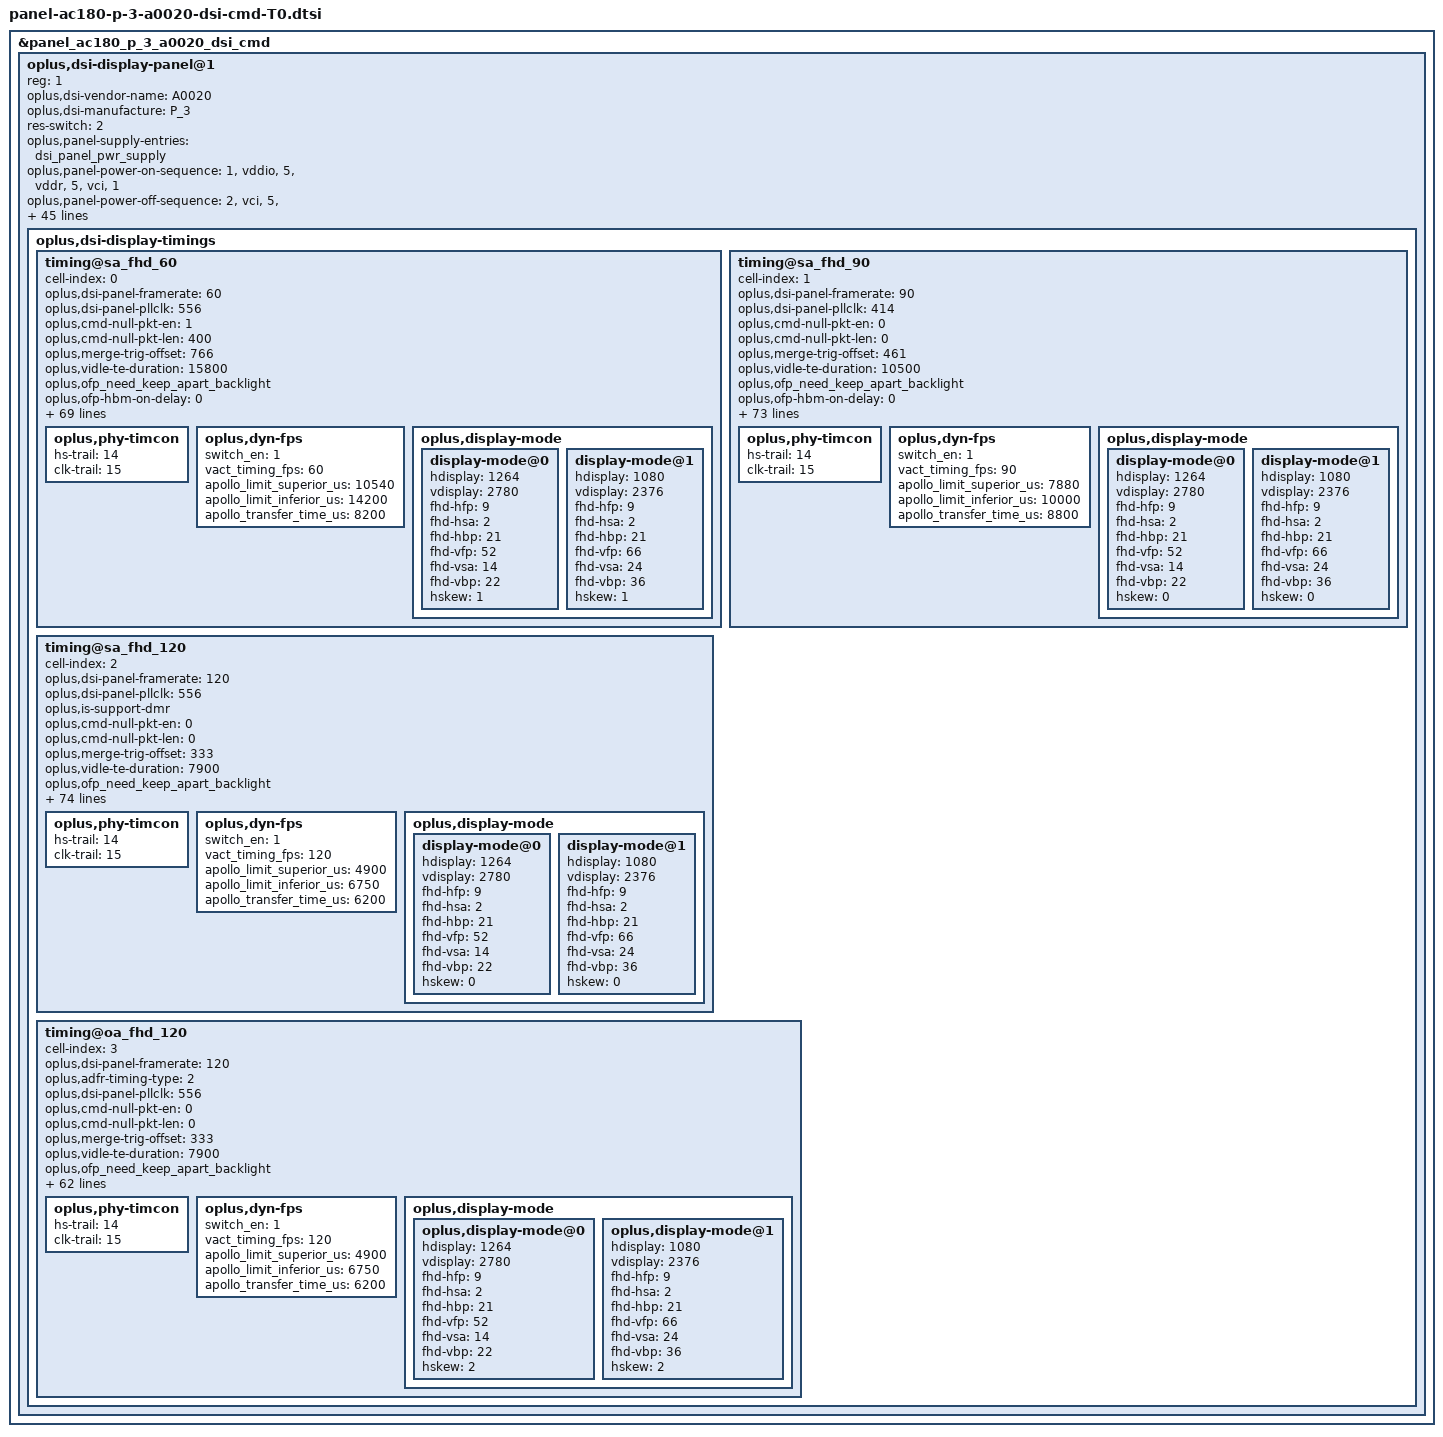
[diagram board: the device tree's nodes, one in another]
&panel_ac180_p_3_a0020_dsi_cmd {
	oplus,dsi-display-panel@1 {
		reg = <1>;
		oplus,dsi-vendor-name = "A0020";
		oplus,dsi-manufacture = "P_3";
		/* round corner */
		#include "panel-ac180-p-3-a0020-dsi-cmd-round-corner.dtsi"
		oplus,dsi-display-timings {
			timing@sa_fhd_60 {
				cell-index = <0>;
				oplus,dsi-panel-framerate = <60>;
				oplus,dsi-panel-pllclk = <556>;
				oplus,cmd-null-pkt-en = <1>;
				oplus,cmd-null-pkt-len = <400>;
				oplus,merge-trig-offset = <766>;
				oplus,vidle-te-duration = <15800>;
				/* OPLUS_FEATURE_DISPLAY_ONSCREENFINGERPRINT */
				oplus,ofp_need_keep_apart_backlight;
				oplus,ofp-hbm-on-delay = <0>;
				oplus,ofp-pre-hbm-off-delay = <12>;
				oplus,ofp-hbm-off-delay = <0>;
				oplus,ofp-need-to-sync-data-in-aod-unlocking;
				oplus,ofp-aod-off-insert-black = <2>;
				oplus,ofp-aod-off-black-frame-total-time = <59>;
				#include "panel-ac180-p-3-a0020-dsi-cmd-common-T0.dtsi"
				oplus,dsi-timing-switch-command = [
					39 00 00 40 00 00 04 FF 5A A5 00
					39 00 00 40 00 00 02 60 00 // 0x00: 120Hz 02: 90Hz
					39 00 00 40 00 00 04 FF 5A A5 53
					39 00 00 40 00 00 03 85 CC E1 // Normal Demura
					39 00 00 40 00 00 04 FF 5A A5 2D
					39 00 00 40 00 00 03 83 01 00
					39 00 00 40 00 00 02 F2 01
					39 00 00 00 00 00 04 FF 5A A5 00
				];
				oplus,dsi-timing-switch-1pulse-command = [
					39 00 00 40 00 00 04 FF 5A A5 00
					39 00 00 40 00 00 02 60 01 // 0x01: 120Hz 03: 90Hz
					39 00 00 40 00 00 04 FF 5A A5 53
					39 00 00 40 00 00 03 85 CC E3 // DC Demura
					39 00 00 40 00 00 04 FF 5A A5 2D
					39 00 00 40 00 00 03 84 01 00
					39 00 00 40 00 00 02 F2 01
					39 00 00 00 00 00 04 FF 5A A5 00
				];
				oplus,dsi-on-command = [
					39 00 00 00 00 00 04 FF 5A A5 08
					39 00 00 00 00 00 02 C8 62 // Sleep out don't reload
					39 00 00 00 00 00 04 FF 5A A5 10 //lhbm mode control begin
					39 00 00 00 00 00 27 8F C8 7C 00 42 00 80 10 00 5A 00 59 58 00 40 1F 00 0D 08 00 05 03 00 02 00 00 00 00 00 00 00 00 00 00 00 00 00 00 00
					39 00 00 00 00 00 04 FF 5A A5 24
					39 00 00 00 00 00 09 A5 0F FF 0F FE 0D BB 0B 1A
					39 00 00 00 00 00 09 A6 07 52 04 8B 04 8A 04 76
					39 00 00 00 00 00 09 A7 03 E6 02 CB 01 E1 01 7D
					39 00 00 00 00 00 09 A8 01 19 00 B5 00 01 00 00
					39 00 00 00 00 00 09 A9 00 00 00 00 00 00 00 00
					39 00 00 00 00 00 09 AA 00 00 00 00 00 00 00 00
					39 00 00 00 00 00 03 AB 00 00
					39 00 00 00 00 00 04 FF 5A A5 29
					39 00 00 00 00 00 09 93 0F FF 0F FE 0D BB 0B 1A
					39 00 00 00 00 00 09 94 07 52 04 8B 04 8A 04 76
					39 00 00 00 00 00 09 95 03 E6 02 CB 01 E1 01 7D
					39 00 00 00 00 00 09 96 01 19 00 B5 00 01 00 00
					39 00 00 00 00 00 09 97 00 00 00 00 00 00 00 00
					39 00 00 00 00 00 09 98 00 00 00 00 00 00 00 00
					39 00 00 00 00 00 09 99 00 00 00 00 00 00 00 00
					39 00 00 00 00 00 05 9A 00 00 00 00
					39 00 00 00 00 00 04 FF 5A A5 00
					39 00 00 00 00 00 02 4F 31
					39 00 00 00 00 00 04 FF 5A A5 1E
					39 00 00 00 00 00 02 80 89
					39 00 00 00 00 00 02 85 10
					39 00 00 00 00 00 02 9A 3F
					39 00 00 00 00 00 02 9B 01
					39 00 00 00 00 00 18 94 00 00 23 00 68 CF 12 58 03 23 D0 BF 46 D0 03 78 58 CF AC 68 23 0E 00
					39 00 00 00 00 00 19 95 00 00 12 00 46 9C 11 14 AE 23 6A 48 45 48 6A 68 AE 14 9B 9C 46 DF 12 00
					39 00 00 00 00 00 0D 96 FD F3 E6 CD B3 9A 80 66 4D 33 1A 00
					39 00 00 00 00 00 13 97 00 29 CC 13 98 30 46 C8 60 79 F8 90 BC 28 C0 EF 58 F0
					39 00 00 00 00 00 04 FF 5A A5 1F
					39 00 00 00 00 00 02 C0 08
					39 00 00 00 00 00 04 FF 5A A5 00
					39 00 00 00 00 00 02 6E 00
					39 00 00 00 00 00 04 FF 5A A5 1E
					39 00 00 00 00 00 02 C0 10
					39 00 00 00 00 00 04 C1 70 9C C1
					39 00 00 00 00 00 09 C2 FF FF FF 61 36 63 46 00
					39 00 00 00 00 00 27 C5 44 00 00 44 00 00 44 00 00 33 FE F7 32 72 77 11 A7 6C 11 3B 08 00 C1 00 00 00 00 00 00 00 00 00 00 00 00 00 00 00
					39 00 00 00 00 00 09 C6 44 00 00 21 00 00 00 80
					39 00 00 00 00 00 27 C7 44 00 00 33 8B 17 21 19 58 11 55 50 10 22 D8 00 99 59 00 00 00 00 00 00 00 00 00 00 00 00 00 00 00 00 00 00 00 00
					39 00 00 00 00 00 09 C8 44 00 00 32 00 00 01 00
					39 00 00 00 00 00 02 C9 30
					39 00 00 00 00 00 04 FF 5A A5 1F
					39 00 00 00 00 00 02 C0 08
					39 00 00 00 00 00 1F C2 FF FF FF AB EA FF FF FF FC FC FF FC FC FC FF FF FF FF FF FF FF FF FF FF FF FF FF FF FF FF
					39 00 00 00 00 00 04 FF 5A A5 24
					39 00 00 00 00 00 02 80 04
					39 00 00 00 00 00 02 81 8B
					39 00 00 00 00 00 02 82 0F
					39 00 00 00 00 00 02 83 FE
					39 00 00 00 00 00 02 84 00
					39 00 00 00 00 00 04 FF 5A A5 00
					39 00 00 00 00 00 02 95 FF
					39 00 00 00 00 00 02 96 09
					39 00 00 00 00 00 02 97 D9
					39 00 00 00 00 00 02 98 02
					39 00 00 00 00 00 02 99 78 //lhbm mode control end
					39 00 00 00 00 00 04 FF 5A A5 07
					39 00 00 00 00 00 02 8A 01 // PPS Enable
					39 00 00 00 00 00 03 8B 11 E0 // PPS Table
					39 00 00 00 00 00 64 80 00 00 00 00 00 12 00 00 A0 21 00 0A DC 04 F0 00 0A 02 78 02 78 01 55 01 D0 00 0A 00 89 00 35 00 0C 0A AB 31 07 08 00 0C 10 07 10 20 00 06 0F 0F 33 0E 1C 2A 38 46 54 62 69 70 77 79 7B 7D 7E 00 82 11 40 19 C0 22 3E 32 7C 3A BA 3A F8 3B 38 3B 38 3B 76 4B 76 4B 74 4B 74 5B B4 73 F4 01 00 00 00 00 00
					39 00 00 00 00 00 64 81 00 00 00 00 00 12 00 00 AB 30 80 0A DC 04 F0 00 14 02 78 02 78 02 00 02 57 00 20 01 F8 00 08 00 0D 05 7A 04 4F 18 00 10 E0 07 10 20 00 06 0F 0F 33 0E 1C 2A 38 46 54 62 69 70 77 79 7B 7D 7E 02 02 22 00 2A 40 2A BE 3A FC 3A FA 3A F8 3B 38 3B 78 3B B6 4B B6 4B F4 4B F4 6C 34 84 74 00 00 00 00 00 00
					39 00 00 00 00 00 02 91 00
					39 00 00 00 00 00 04 FF 5A A5 07
					39 00 00 00 00 00 03 8B 11 A0
					39 00 00 00 00 00 04 FF 5A A5 14
					39 00 00 00 00 00 02 82 01 // SPR IN AP ON
					39 00 00 00 00 00 04 FF 5A A5 21
					39 00 00 00 00 00 02 A4 18 // Flash reload enable
					39 00 00 00 00 00 04 FF 5A A5 13
					39 00 00 00 00 00 03 FB 18 27 // Hole related
					39 00 00 00 00 00 04 FF 5A A5 2D
					39 00 00 00 00 00 02 F2 01 // 0x00:120Hz 01:60Hz
					39 00 00 00 00 00 03 83 01 00 // 60Hz skip frame
					39 00 00 00 00 00 03 84 00 00 // 120Hz skip frame (1pulse)
					39 00 00 00 00 00 03 85 00 00 // 90Hz skip frame
					39 00 00 00 00 00 03 86 00 00 // 90Hz skip frame (1pulse)
					39 00 00 00 00 00 04 FF 5A A5 00
					39 00 00 00 00 00 02 5A 01 // ADFR
					39 00 00 00 00 00 02 5B 80 // ADFR
					39 00 00 00 00 00 04 FF 5A A5 02
					39 00 00 00 00 00 02 C0 03
					39 00 00 00 00 00 04 FF 5A A5 2D
					39 00 00 00 00 00 04 EC 01 AF 00
					39 00 00 00 00 00 03 93 A0 00
					39 00 00 00 00 00 03 94 C4 00
					39 00 00 00 00 00 03 95 00 00
					39 00 00 00 00 00 03 96 00 00
					39 00 00 00 00 00 03 ED D5 00
					39 00 00 00 00 00 04 EE 00 00 00
					/* decreasing step */
					39 00 00 00 00 00 02 97 03
					39 00 00 00 00 00 02 B1 03
					39 00 00 00 00 00 03 98 03 00
					39 00 00 00 00 00 03 99 05 00
					39 00 00 00 00 00 03 9A 0B 00
					39 00 00 00 00 00 03 9B 17 00
					39 00 00 00 00 00 03 A0 00 00
					39 00 00 00 00 00 03 A1 01 02
					39 00 00 00 00 00 02 B2 02
					39 00 00 00 00 00 02 B3 04
					39 00 00 00 00 00 02 B4 08
					39 00 00 00 00 00 02 B5 11
					39 00 00 00 00 00 03 BA 00 00
					39 00 00 00 00 00 03 BB 01 02
					39 00 00 00 00 00 04 FF 5A A5 02
					39 00 00 00 00 00 09 B0 00 80 00 10 00 00 00 00
					39 00 00 00 00 00 03 AB AF 82 // TE Left Shift 2ms
					39 00 00 00 00 00 04 FF 5A A5 31
					39 00 00 00 00 00 02 A0 A1 // CTB ON
					39 00 00 00 00 00 04 FF 5A A5 49
					39 00 00 00 00 00 02 E0 01 // ODC ON
					39 00 00 00 00 00 04 FF 5A A5 53
					39 00 00 00 00 00 03 80 0F 40 // Demura ON
					39 00 00 00 00 00 03 85 CC E1 // Loading demura data
					39 00 00 00 00 00 04 FF 5A A5 17
					39 00 00 00 00 00 02 A0 00 // RCN OFF
					/* AVEE PUMP 4H */
					39 00 00 00 00 00 04 FF 5A A5 02
					39 00 00 00 00 00 0A E5 09 0B 0B 0D 55 0D 32 32 32
					39 00 00 00 00 00 03 E7 33 25
					39 00 00 00 00 00 03 E8 33 25
					39 00 00 00 00 00 03 E9 33 25
					39 00 00 00 00 00 03 EA 33 25
					39 00 00 00 00 00 04 FF 5A A5 12
					39 00 00 00 00 00 02 81 33 // SRC keep vsp 2 frame
					39 00 00 00 00 00 04 FF 5A A5 00
					39 00 00 00 00 00 02 5E 01 // Skip frame Enable
					39 00 00 00 00 00 02 60 00 // Normal mode: 60Hz (6pulse)
					39 00 00 00 00 00 02 61 07 // AOD in mode
					39 00 00 00 00 00 02 35 00 // TE On
					39 00 00 00 00 00 02 53 20 // BC On Dimming OFF

					/* 3D LUT register */
					/* 3D LUT switch */
					39 00 00 40 00 00 04 FF 5A A5 00
					15 00 00 40 00 00 02 4D 00
					/* Gray binding points and DBV */
					39 00 00 40 00 00 04 FF 5A A5 4F
					15 00 00 40 00 00 02 91 00
					15 00 00 40 00 00 02 92 00
					15 00 00 40 00 00 02 93 08
					15 00 00 40 00 00 02 94 00
					15 00 00 40 00 00 02 95 10
					15 00 00 40 00 00 02 96 00
					15 00 00 40 00 00 02 97 20
					15 00 00 40 00 00 02 98 00
					15 00 00 40 00 00 02 99 20
					15 00 00 40 00 00 02 9A 00
					15 00 00 40 00 00 02 A0 00
					15 00 00 40 00 00 02 A1 01
					15 00 00 40 00 00 02 A2 0A
					15 00 00 40 00 00 02 A3 81
					15 00 00 40 00 00 02 A4 0F
					15 00 00 40 00 00 02 A5 FF
					/* Matrix_off && LUT3D_off && Gray2bypass */
					15 00 00 40 00 00 02 AC 0C
					/* Gamma && Degamma */
					39 00 00 40 00 00 04 FF 5A A5 13
					15 00 00 40 00 00 02 CA 70
					/* 125 point mapping value for DBV1 */
					39 00 00 40 00 00 04 FF 5A A5 70
					39 00 00 40 00 00 07 80 00 00 00 00 00 00
					39 00 00 40 00 00 07 81 00 00 00 00 09 99
					39 00 00 40 00 00 07 82 00 00 00 00 13 33
					39 00 00 40 00 00 07 83 00 00 00 00 20 04
					39 00 00 40 00 00 07 84 00 00 00 00 3F BC
					39 00 00 40 00 00 07 85 00 00 08 04 00 00
					39 00 00 40 00 00 07 86 00 00 08 04 08 04
					39 00 00 40 00 00 07 87 00 00 08 04 10 04
					39 00 00 40 00 00 07 88 00 00 08 04 20 04
					39 00 00 40 00 00 07 89 00 00 08 04 3F BC
					39 00 00 40 00 00 07 8A 00 00 10 04 00 00
					39 00 00 40 00 00 07 8B 00 00 10 04 08 04
					39 00 00 40 00 00 07 8C 00 00 10 04 10 04
					39 00 00 40 00 00 07 8D 00 00 10 04 20 04
					39 00 00 40 00 00 07 8E 00 00 10 04 3F BC
					39 00 00 40 00 00 07 8F 00 00 20 04 00 00
					39 00 00 40 00 00 07 90 00 00 20 04 08 04
					39 00 00 40 00 00 07 91 00 00 20 04 10 04
					39 00 00 40 00 00 07 92 00 00 20 04 20 04
					39 00 00 40 00 00 07 93 00 00 20 04 3F BC
					39 00 00 40 00 00 07 94 00 00 3F BC 00 00
					39 00 00 40 00 00 07 95 00 00 3F BC 08 04
					39 00 00 40 00 00 07 96 00 00 3F BC 10 04
					39 00 00 40 00 00 07 97 00 00 3F BC 20 04
					39 00 00 40 00 00 07 98 00 00 3F BC 3F BC
					39 00 00 40 00 00 07 99 04 CC 00 00 00 00
					39 00 00 40 00 00 07 9A 08 04 00 00 08 04
					39 00 00 40 00 00 07 9B 08 04 00 00 10 04
					39 00 00 40 00 00 07 9C 08 04 00 00 20 04
					39 00 00 40 00 00 07 9D 08 04 00 00 3F BC
					39 00 00 40 00 00 07 9E 08 04 08 04 00 00
					39 00 00 40 00 00 07 9F 04 CC 08 00 09 99
					39 00 00 40 00 00 07 A0 08 04 08 04 10 04
					39 00 00 40 00 00 07 A1 08 04 08 04 20 04
					39 00 00 40 00 00 07 A2 08 04 08 04 3F BC
					39 00 00 40 00 00 07 A3 08 04 10 04 00 00
					39 00 00 40 00 00 07 A4 08 04 10 04 08 04
					39 00 00 40 00 00 07 A5 08 04 10 04 10 04
					39 00 00 40 00 00 07 A6 08 04 10 04 20 04
					39 00 00 40 00 00 07 A7 08 04 10 04 3F BC
					39 00 00 40 00 00 07 A8 08 04 20 04 00 00
					39 00 00 40 00 00 07 A9 08 04 20 04 08 04
					39 00 00 40 00 00 07 AA 08 04 20 04 10 04
					39 00 00 40 00 00 07 AB 08 04 20 04 20 04
					39 00 00 40 00 00 07 AC 08 04 20 04 3F BC
					39 00 00 40 00 00 07 AD 08 04 3F BC 00 00
					39 00 00 40 00 00 07 AE 08 04 3F BC 08 04
					39 00 00 40 00 00 07 AF 08 04 3F BC 10 04
					39 00 00 40 00 00 07 B0 08 04 3F BC 20 04
					39 00 00 40 00 00 07 B1 08 04 3F BC 3F BC
					39 00 00 40 00 00 07 B2 09 99 00 00 00 00
					39 00 00 40 00 00 07 B3 10 04 00 00 08 04
					39 00 00 40 00 00 07 B4 10 04 00 00 10 04
					39 00 00 40 00 00 07 B5 10 04 00 00 20 04
					39 00 00 40 00 00 07 B6 10 04 00 00 3F BC
					39 00 00 40 00 00 07 B7 10 04 08 04 00 00
					39 00 00 40 00 00 07 B8 10 04 08 04 08 04
					39 00 00 40 00 00 07 B9 10 04 08 04 10 04
					39 00 00 40 00 00 07 BA 10 04 08 04 20 04
					39 00 00 40 00 00 07 BB 10 04 08 04 3F BC
					39 00 00 40 00 00 07 BC 10 04 10 04 00 00
					39 00 00 40 00 00 07 BD 10 04 10 04 08 04
					39 00 00 40 00 00 07 BE 09 99 10 04 13 33
					39 00 00 40 00 00 07 BF 10 04 10 04 20 04
					39 00 00 40 00 00 07 C0 10 04 10 04 3F BC
					39 00 00 40 00 00 07 C1 10 04 20 04 00 00
					39 00 00 40 00 00 07 C2 10 04 20 04 08 04
					39 00 00 40 00 00 07 C3 10 04 20 04 10 04
					39 00 00 40 00 00 07 C4 10 04 20 04 20 04
					39 00 00 40 00 00 07 C5 10 04 20 04 3F BC
					39 00 00 40 00 00 07 C6 10 04 3F BC 00 00
					39 00 00 40 00 00 07 C7 10 04 3F BC 08 04
					39 00 00 40 00 00 07 C8 10 04 3F BC 10 04
					39 00 00 40 00 00 07 C9 10 04 3F BC 20 04
					39 00 00 40 00 00 07 CA 10 04 3F BC 3F BC
					39 00 00 40 00 00 07 CB 20 04 00 00 00 00
					39 00 00 40 00 00 07 CC 20 04 00 00 08 04
					39 00 00 40 00 00 07 CD 20 04 00 00 10 04
					39 00 00 40 00 00 07 CE 20 04 00 00 20 04
					39 00 00 40 00 00 07 CF 20 04 00 00 3F BC
					39 00 00 40 00 00 07 D0 20 04 08 04 00 00
					39 00 00 40 00 00 07 D1 20 04 08 04 08 04
					39 00 00 40 00 00 07 D2 20 04 08 04 10 04
					39 00 00 40 00 00 07 D3 20 04 08 04 20 04
					39 00 00 40 00 00 07 D4 20 04 08 04 3F BC
					39 00 00 40 00 00 07 D5 20 04 10 04 00 00
					39 00 00 40 00 00 07 D6 20 04 10 04 08 04
					39 00 00 40 00 00 07 D7 20 04 10 04 10 04
					39 00 00 40 00 00 07 D8 20 04 10 04 20 04
					39 00 00 40 00 00 07 D9 20 04 10 04 3F BC
					39 00 00 40 00 00 07 DA 20 04 20 04 00 00
					39 00 00 40 00 00 07 DB 20 04 20 04 08 04
					39 00 00 40 00 00 07 DC 20 04 20 04 10 04
					39 00 00 40 00 00 07 DD 20 00 20 00 20 00
					39 00 00 40 00 00 07 DE 20 04 20 04 3F BC
					39 00 00 40 00 00 07 DF 20 04 3F BC 00 00
					39 00 00 40 00 00 07 E0 20 04 3F BC 08 04
					39 00 00 40 00 00 07 E1 20 04 3F BC 10 04
					39 00 00 40 00 00 07 E2 20 04 3F BC 20 04
					39 00 00 40 00 00 07 E3 20 04 3F BC 3F BC
					39 00 00 40 00 00 07 E4 3F BC 00 00 00 00
					39 00 00 40 00 00 07 E5 3F BC 00 00 08 04
					39 00 00 40 00 00 07 E6 3F BC 00 00 10 04
					39 00 00 40 00 00 07 E7 3F BC 00 00 20 04
					39 00 00 40 00 00 07 E8 3F BC 00 00 3F BC
					39 00 00 40 00 00 07 E9 3F BC 08 04 00 00
					39 00 00 40 00 00 07 EA 3F BC 08 04 08 04
					39 00 00 40 00 00 07 EB 3F BC 08 04 10 04
					39 00 00 40 00 00 07 EC 3F BC 08 04 20 04
					39 00 00 40 00 00 07 ED 3F BC 08 04 3F BC
					39 00 00 40 00 00 07 EE 3F BC 10 04 00 00
					39 00 00 40 00 00 07 EF 3F BC 10 04 08 04
					39 00 00 40 00 00 07 F0 3F BC 10 04 10 04
					39 00 00 40 00 00 07 F1 3F BC 10 04 20 04
					39 00 00 40 00 00 07 F2 3F BC 10 04 3F BC
					39 00 00 40 00 00 07 F3 3F BC 20 04 00 00
					39 00 00 40 00 00 07 F4 3F BC 20 04 08 04
					39 00 00 40 00 00 07 F5 3F BC 20 04 10 04
					39 00 00 40 00 00 07 F6 3F BC 20 04 20 04
					39 00 00 40 00 00 07 F7 3F BC 20 04 3F BC
					39 00 00 40 00 00 07 F8 3F BC 3F BC 00 00
					39 00 00 40 00 00 07 F9 3F BC 3F BC 08 04
					39 00 00 40 00 00 07 FA 3F BC 3F BC 10 04
					39 00 00 40 00 00 07 FB 3F BC 3F BC 20 04
					39 00 00 40 00 00 07 FC 3F C0 3F C0 3F C0
					/* 125 point mapping value for DBV2 */
					39 00 00 40 00 00 04 FF 5A A5 71
					39 00 00 40 00 00 07 80 00 00 00 00 00 00
					39 00 00 40 00 00 07 81 00 00 00 00 09 99
					39 00 00 40 00 00 07 82 00 00 00 00 13 33
					39 00 00 40 00 00 07 83 00 00 00 00 20 04
					39 00 00 40 00 00 07 84 00 00 00 00 3F BC
					39 00 00 40 00 00 07 85 00 00 08 04 00 00
					39 00 00 40 00 00 07 86 00 00 08 04 08 04
					39 00 00 40 00 00 07 87 00 00 08 04 10 04
					39 00 00 40 00 00 07 88 00 00 08 04 20 04
					39 00 00 40 00 00 07 89 00 00 08 04 3F BC
					39 00 00 40 00 00 07 8A 00 00 10 04 00 00
					39 00 00 40 00 00 07 8B 00 00 10 04 08 04
					39 00 00 40 00 00 07 8C 00 00 10 04 10 04
					39 00 00 40 00 00 07 8D 00 00 10 04 20 04
					39 00 00 40 00 00 07 8E 00 00 10 04 3F BC
					39 00 00 40 00 00 07 8F 00 00 20 04 00 00
					39 00 00 40 00 00 07 90 00 00 20 04 08 04
					39 00 00 40 00 00 07 91 00 00 20 04 10 04
					39 00 00 40 00 00 07 92 00 00 20 04 20 04
					39 00 00 40 00 00 07 93 00 00 20 04 3F BC
					39 00 00 40 00 00 07 94 00 00 3F BC 00 00
					39 00 00 40 00 00 07 95 00 00 3F BC 08 04
					39 00 00 40 00 00 07 96 00 00 3F BC 10 04
					39 00 00 40 00 00 07 97 00 00 3F BC 20 04
					39 00 00 40 00 00 07 98 00 00 3F BC 3F BC
					39 00 00 40 00 00 07 99 04 CC 00 00 00 00
					39 00 00 40 00 00 07 9A 08 04 00 00 08 04
					39 00 00 40 00 00 07 9B 08 04 00 00 10 04
					39 00 00 40 00 00 07 9C 08 04 00 00 20 04
					39 00 00 40 00 00 07 9D 08 04 00 00 3F BC
					39 00 00 40 00 00 07 9E 08 04 08 04 00 00
					39 00 00 40 00 00 07 9F 04 CC 08 00 09 99
					39 00 00 40 00 00 07 A0 08 04 08 04 10 04
					39 00 00 40 00 00 07 A1 08 04 08 04 20 04
					39 00 00 40 00 00 07 A2 08 04 08 04 3F BC
					39 00 00 40 00 00 07 A3 08 04 10 04 00 00
					39 00 00 40 00 00 07 A4 08 04 10 04 08 04
					39 00 00 40 00 00 07 A5 08 04 10 04 10 04
					39 00 00 40 00 00 07 A6 08 04 10 04 20 04
					39 00 00 40 00 00 07 A7 08 04 10 04 3F BC
					39 00 00 40 00 00 07 A8 08 04 20 04 00 00
					39 00 00 40 00 00 07 A9 08 04 20 04 08 04
					39 00 00 40 00 00 07 AA 08 04 20 04 10 04
					39 00 00 40 00 00 07 AB 08 04 20 04 20 04
					39 00 00 40 00 00 07 AC 08 04 20 04 3F BC
					39 00 00 40 00 00 07 AD 08 04 3F BC 00 00
					39 00 00 40 00 00 07 AE 08 04 3F BC 08 04
					39 00 00 40 00 00 07 AF 08 04 3F BC 10 04
					39 00 00 40 00 00 07 B0 08 04 3F BC 20 04
					39 00 00 40 00 00 07 B1 08 04 3F BC 3F BC
					39 00 00 40 00 00 07 B2 09 99 00 00 00 00
					39 00 00 40 00 00 07 B3 10 04 00 00 08 04
					39 00 00 40 00 00 07 B4 10 04 00 00 10 04
					39 00 00 40 00 00 07 B5 10 04 00 00 20 04
					39 00 00 40 00 00 07 B6 10 04 00 00 3F BC
					39 00 00 40 00 00 07 B7 10 04 08 04 00 00
					39 00 00 40 00 00 07 B8 10 04 08 04 08 04
					39 00 00 40 00 00 07 B9 10 04 08 04 10 04
					39 00 00 40 00 00 07 BA 10 04 08 04 20 04
					39 00 00 40 00 00 07 BB 10 04 08 04 3F BC
					39 00 00 40 00 00 07 BC 10 04 10 04 00 00
					39 00 00 40 00 00 07 BD 10 04 10 04 08 04
					39 00 00 40 00 00 07 BE 09 99 10 04 13 33
					39 00 00 40 00 00 07 BF 10 04 10 04 20 04
					39 00 00 40 00 00 07 C0 10 04 10 04 3F BC
					39 00 00 40 00 00 07 C1 10 04 20 04 00 00
					39 00 00 40 00 00 07 C2 10 04 20 04 08 04
					39 00 00 40 00 00 07 C3 10 04 20 04 10 04
					39 00 00 40 00 00 07 C4 10 04 20 04 20 04
					39 00 00 40 00 00 07 C5 10 04 20 04 3F BC
					39 00 00 40 00 00 07 C6 10 04 3F BC 00 00
					39 00 00 40 00 00 07 C7 10 04 3F BC 08 04
					39 00 00 40 00 00 07 C8 10 04 3F BC 10 04
					39 00 00 40 00 00 07 C9 10 04 3F BC 20 04
					39 00 00 40 00 00 07 CA 10 04 3F BC 3F BC
					39 00 00 40 00 00 07 CB 20 04 00 00 00 00
					39 00 00 40 00 00 07 CC 20 04 00 00 08 04
					39 00 00 40 00 00 07 CD 20 04 00 00 10 04
					39 00 00 40 00 00 07 CE 20 04 00 00 20 04
					39 00 00 40 00 00 07 CF 20 04 00 00 3F BC
					39 00 00 40 00 00 07 D0 20 04 08 04 00 00
					39 00 00 40 00 00 07 D1 20 04 08 04 08 04
					39 00 00 40 00 00 07 D2 20 04 08 04 10 04
					39 00 00 40 00 00 07 D3 20 04 08 04 20 04
					39 00 00 40 00 00 07 D4 20 04 08 04 3F BC
					39 00 00 40 00 00 07 D5 20 04 10 04 00 00
					39 00 00 40 00 00 07 D6 20 04 10 04 08 04
					39 00 00 40 00 00 07 D7 20 04 10 04 10 04
					39 00 00 40 00 00 07 D8 20 04 10 04 20 04
					39 00 00 40 00 00 07 D9 20 04 10 04 3F BC
					39 00 00 40 00 00 07 DA 20 04 20 04 00 00
					39 00 00 40 00 00 07 DB 20 04 20 04 08 04
					39 00 00 40 00 00 07 DC 20 04 20 04 10 04
					39 00 00 40 00 00 07 DD 20 00 20 00 20 00
					39 00 00 40 00 00 07 DE 20 04 20 04 3F BC
					39 00 00 40 00 00 07 DF 20 04 3F BC 00 00
					39 00 00 40 00 00 07 E0 20 04 3F BC 08 04
					39 00 00 40 00 00 07 E1 20 04 3F BC 10 04
					39 00 00 40 00 00 07 E2 20 04 3F BC 20 04
					39 00 00 40 00 00 07 E3 20 04 3F BC 3F BC
					39 00 00 40 00 00 07 E4 3F BC 00 00 00 00
					39 00 00 40 00 00 07 E5 3F BC 00 00 08 04
					39 00 00 40 00 00 07 E6 3F BC 00 00 10 04
					39 00 00 40 00 00 07 E7 3F BC 00 00 20 04
					39 00 00 40 00 00 07 E8 3F BC 00 00 3F BC
					39 00 00 00 00 00 07 E9 3F BC 08 04 00 00
					39 00 00 40 00 00 07 EA 3F BC 08 04 08 04
					39 00 00 40 00 00 07 EB 3F BC 08 04 10 04
					39 00 00 40 00 00 07 EC 3F BC 08 04 20 04
					39 00 00 40 00 00 07 ED 3F BC 08 04 3F BC
					39 00 00 40 00 00 07 EE 3F BC 10 04 00 00
					39 00 00 40 00 00 07 EF 3F BC 10 04 08 04
					39 00 00 40 00 00 07 F0 3F BC 10 04 10 04
					39 00 00 40 00 00 07 F1 3F BC 10 04 20 04
					39 00 00 40 00 00 07 F2 3F BC 10 04 3F BC
					39 00 00 40 00 00 07 F3 3F BC 20 04 00 00
					39 00 00 40 00 00 07 F4 3F BC 20 04 08 04
					39 00 00 40 00 00 07 F5 3F BC 20 04 10 04
					39 00 00 40 00 00 07 F6 3F BC 20 04 20 04
					39 00 00 40 00 00 07 F7 3F BC 20 04 3F BC
					39 00 00 40 00 00 07 F8 3F BC 3F BC 00 00
					39 00 00 40 00 00 07 F9 3F BC 3F BC 08 04
					39 00 00 40 00 00 07 FA 3F BC 3F BC 10 04
					39 00 00 40 00 00 07 FB 3F BC 3F BC 20 04
					39 00 00 00 00 00 07 FC 3F C0 3F C0 3F C0

					05 00 00 00 78 00 01 11 // Sleep OUT
					/* TE raise */
					39 00 00 00 00 00 04 FF 5A A5 22
					39 00 00 00 00 00 08 D8 00 DB 11 10 32 14 14
					39 00 00 00 00 00 08 D9 00 DB 11 10 32 14 14
					39 00 00 00 00 00 08 DA 00 DB 11 10 32 14 14
					39 00 00 00 00 00 08 DB 00 DB 11 10 32 14 14
					39 00 00 00 00 00 0A DC 84 94 BB 00 20 C4 A1 CC 10
					39 00 00 00 00 00 02 DD 01
					39 00 00 00 00 00 02 DE F1
					39 00 00 00 00 00 02 DF 80
					39 00 00 00 00 00 08 E0 02 00 5F 21 00 28 00
					39 00 00 00 00 00 04 FF 5A A5 00
					39 00 00 00 00 00 01 29 // Display ON
				];
				oplus,dsi-aod-off-command = [
					39 00 00 40 00 00 04 FF 5A A5 02
					39 00 00 40 00 00 03 AB AF 82 //TE Shift ON
					39 00 00 40 00 00 03 88 C0 00
					39 00 00 40 00 00 04 FF 5A A5 00
					39 00 00 40 00 00 02 38 00
					39 00 00 00 00 00 05 51 00 00 00 00
				];
				oplus,dsi-ultra-low-power-aod-on-command = [
					39 00 00 40 00 00 04 FF 5A A5 2D
					39 00 00 40 00 00 03 8A 1D 00
					39 00 00 00 00 00 04 FF 5A A5 00
				];
				oplus,dsi-ultra-low-power-aod-off-command = [
					39 00 00 40 00 00 04 FF 5A A5 2D
					39 00 00 40 00 00 03 8A 00 00
					39 00 00 00 00 00 04 FF 5A A5 00
				];
				oplus,dsi-hbm-on-command = [
					39 00 00 00 00 00 03 51 0E E0
				];
				oplus,dsi-hbm-off-command = [
					39 00 00 00 00 00 03 51 0D BB
				];
				oplus,dsi-adfr-min-fps-60hz-command = [
					39 00 00 40 00 00 04 FF 5A A5 2D
					39 00 00 40 00 00 03 83 01 00
					39 00 00 40 00 00 03 84 01 00
					39 00 00 00 00 00 04 FF 5A A5 00
				];
				oplus,dsi-adfr-min-fps-30hz-command = [
					39 00 00 40 00 00 04 FF 5A A5 2D
					39 00 00 40 00 00 03 83 03 00
					39 00 00 40 00 00 03 84 03 00
					39 00 00 00 00 00 04 FF 5A A5 00
				];
				oplus,dsi-adfr-min-fps-20hz-command = [
					39 00 00 40 00 00 04 FF 5A A5 2D
					39 00 00 40 00 00 03 83 05 00
					39 00 00 40 00 00 03 84 05 00
					39 00 00 00 00 00 04 FF 5A A5 00
				];
				oplus,dsi-adfr-min-fps-10hz-command = [
					39 00 00 40 00 00 04 FF 5A A5 2D
					39 00 00 40 00 00 03 83 0B 00
					39 00 00 40 00 00 03 84 0B 00
					39 00 00 00 00 00 04 FF 5A A5 00
				];
				oplus,dsi-adfr-min-fps-5hz-command = [
					39 00 00 40 00 00 04 FF 5A A5 2D
					39 00 00 40 00 00 03 83 17 00
					39 00 00 40 00 00 03 84 17 00
					39 00 00 00 00 00 04 FF 5A A5 00
				];
				oplus,dsi-adfr-min-fps-1hz-command = [
					39 00 00 40 00 00 04 FF 5A A5 2D
					39 00 00 40 00 00 03 83 77 00
					39 00 00 40 00 00 03 84 77 00
					39 00 00 00 00 00 04 FF 5A A5 00
				];
				oplus,dsi-pwm-switch-1to3pul-command = [
					39 00 00 40 00 00 04 FF 5A A5 53
					39 00 00 40 00 00 03 85 CC E1 // Normal Demura
					39 00 00 40 00 00 04 FF 5A A5 00
					39 00 00 00 00 00 02 60 00
				];
				oplus,dsi-pwm-switch-3to1pul-command = [
					39 00 00 40 00 00 04 FF 5A A5 53
					39 00 00 40 00 00 03 85 CC E3 // DC Demura
					39 00 00 40 00 00 04 FF 5A A5 00
					39 00 00 00 00 00 02 60 01
				];

				oplus,dsi-timing-switch-command-state = "dsi_hs_mode";
				oplus,dsi-timing-switch-1pulse-command-state = "dsi_hs_mode";
				oplus,dsi-on-command-state = "dsi_lp_mode";
				oplus,dsi-aod-off-command-state = "dsi_ls_mode";
				oplus,dsi-ultra-low-power-aod-off-command-state = "dsi_ls_mode";
				oplus,dsi-ultra-low-power-aod-on-command-state = "dsi_ls_mode";
				oplus,dsi-hbm-on-command-state = "dsi_hs_mode";
				oplus,dsi-hbm-off-command-state = "dsi_hs_mode";
				oplus,dsi-auto-off-minfps-command-state = "dsi_hs_mode";
				oplus,dsi-pwm-switch-1to3pul-command-state = "dsi_hs_mode";
				oplus,dsi-pwm-switch-3to1pul-command-state = "dsi_hs_mode";
				oplus,dsi-adfr-min-fps-60hz-command-state = "dsi_hs_mode";
				oplus,dsi-adfr-min-fps-30hz-command-state = "dsi_hs_mode";
				oplus,dsi-adfr-min-fps-20hz-command-state = "dsi_hs_mode";
				oplus,dsi-adfr-min-fps-10hz-command-state = "dsi_hs_mode";
				oplus,dsi-adfr-min-fps-5hz-command-state = "dsi_hs_mode";
				oplus,dsi-adfr-min-fps-1hz-command-state = "dsi_hs_mode";
				oplus,dsc-params-entries = <&dsc_params>;
				oplus,spr-params-entries = <&spr_params>;
				oplus,phy-timcon {
					hs-trail = <14>;
					clk-trail = <15>;
				};
				oplus,dyn-fps {
					switch_en = <1>;
					vact_timing_fps = <60>;
					apollo_limit_superior_us = <10540>;
					apollo_limit_inferior_us = <14200>;
					apollo_transfer_time_us = <8200>;
				};
				oplus,display-mode {
					display-mode@0 {
						hdisplay = <1264>;
						vdisplay = <2780>;
						fhd-hfp = <9>;
						fhd-hsa = <2>;
						fhd-hbp = <21>;
						fhd-vfp = <52>;
						fhd-vsa = <14>;
						fhd-vbp = <22>;
						hskew = <1>;
					};
					display-mode@1 {
						hdisplay = <1080>;
						vdisplay = <2376>;
						fhd-hfp = <9>;
						fhd-hsa = <2>;
						fhd-hbp = <21>;
						fhd-vfp = <66>;
						fhd-vsa = <24>;
						fhd-vbp = <36>;
						hskew = <1>;
					};
				};
			};
			timing@sa_fhd_90 {
				cell-index = <1>;
				oplus,dsi-panel-framerate = <90>;
				oplus,dsi-panel-pllclk = <414>;
				oplus,cmd-null-pkt-en = <0>;
				oplus,cmd-null-pkt-len = <0>;
				oplus,merge-trig-offset = <461>;
				oplus,vidle-te-duration = <10500>;
				/* OPLUS_FEATURE_DISPLAY_ONSCREENFINGERPRINT */
				oplus,ofp_need_keep_apart_backlight;
				oplus,ofp-hbm-on-delay = <0>;
				oplus,ofp-pre-hbm-off-delay = <9>;
				oplus,ofp-hbm-off-delay = <0>;
				oplus,ofp-need-to-sync-data-in-aod-unlocking;
				oplus,ofp-aod-off-insert-black = <2>;
				oplus,ofp-aod-off-black-frame-total-time = <45>;
				#include "panel-ac180-p-3-a0020-dsi-cmd-common-T0.dtsi"
				oplus,dsi-timing-switch-command = [
					39 00 00 40 00 00 04 FF 5A A5 00
					39 00 00 40 00 00 02 60 02 // 0x00: 120Hz 02: 90Hz
					39 00 00 40 00 00 04 FF 5A A5 53
					39 00 00 40 00 00 03 85 CC E1 // Normal Demura
					39 00 00 40 00 00 04 FF 5A A5 2D
					39 00 00 40 00 00 03 85 00 00
					39 00 00 40 00 00 02 F2 00
					39 00 00 00 00 00 04 FF 5A A5 00
				];
				oplus,dsi-timing-switch-1pulse-command = [
					39 00 00 40 00 00 04 FF 5A A5 00
					39 00 00 40 00 00 02 60 03 // 0x01: 120Hz 03: 90Hz
					39 00 00 40 00 00 04 FF 5A A5 53
					39 00 00 40 00 00 03 85 CC E3 // DC Demura
					39 00 00 40 00 00 04 FF 5A A5 2D
					39 00 00 40 00 00 03 86 00 00
					39 00 00 40 00 00 02 F2 00
					39 00 00 00 00 00 04 FF 5A A5 00
				];
				oplus,dsi-on-command = [
					39 00 00 00 00 00 04 FF 5A A5 08
					39 00 00 00 00 00 02 C8 62 // Sleep out don't reload
					39 00 00 00 00 00 04 FF 5A A5 10 //lhbm mode control begin
					39 00 00 00 00 00 27 8F C8 7C 00 42 00 80 10 00 5A 00 59 58 00 40 1F 00 0D 08 00 05 03 00 02 00 00 00 00 00 00 00 00 00 00 00 00 00 00 00
					39 00 00 00 00 00 04 FF 5A A5 24
					39 00 00 00 00 00 09 A5 0F FF 0F FE 0D BB 0B 1A
					39 00 00 00 00 00 09 A6 07 52 04 8B 04 8A 04 76
					39 00 00 00 00 00 09 A7 03 E6 02 CB 01 E1 01 7D
					39 00 00 00 00 00 09 A8 01 19 00 B5 00 01 00 00
					39 00 00 00 00 00 09 A9 00 00 00 00 00 00 00 00
					39 00 00 00 00 00 09 AA 00 00 00 00 00 00 00 00
					39 00 00 00 00 00 03 AB 00 00
					39 00 00 00 00 00 04 FF 5A A5 29
					39 00 00 00 00 00 09 93 0F FF 0F FE 0D BB 0B 1A
					39 00 00 00 00 00 09 94 07 52 04 8B 04 8A 04 76
					39 00 00 00 00 00 09 95 03 E6 02 CB 01 E1 01 7D
					39 00 00 00 00 00 09 96 01 19 00 B5 00 01 00 00
					39 00 00 00 00 00 09 97 00 00 00 00 00 00 00 00
					39 00 00 00 00 00 09 98 00 00 00 00 00 00 00 00
					39 00 00 00 00 00 09 99 00 00 00 00 00 00 00 00
					39 00 00 00 00 00 05 9A 00 00 00 00
					39 00 00 00 00 00 04 FF 5A A5 00
					39 00 00 00 00 00 02 4F 31
					39 00 00 00 00 00 04 FF 5A A5 1E
					39 00 00 00 00 00 02 80 89
					39 00 00 00 00 00 02 85 10
					39 00 00 00 00 00 02 9A 3F
					39 00 00 00 00 00 02 9B 01
					39 00 00 00 00 00 18 94 00 00 23 00 68 CF 12 58 03 23 D0 BF 46 D0 03 78 58 CF AC 68 23 0E 00
					39 00 00 00 00 00 19 95 00 00 12 00 46 9C 11 14 AE 23 6A 48 45 48 6A 68 AE 14 9B 9C 46 DF 12 00
					39 00 00 00 00 00 0D 96 FD F3 E6 CD B3 9A 80 66 4D 33 1A 00
					39 00 00 00 00 00 13 97 00 29 CC 13 98 30 46 C8 60 79 F8 90 BC 28 C0 EF 58 F0
					39 00 00 00 00 00 04 FF 5A A5 1F
					39 00 00 00 00 00 02 C0 08
					39 00 00 00 00 00 04 FF 5A A5 00
					39 00 00 00 00 00 02 6E 00
					39 00 00 00 00 00 04 FF 5A A5 1E
					39 00 00 00 00 00 02 C0 10
					39 00 00 00 00 00 04 C1 70 9C C1
					39 00 00 00 00 00 09 C2 FF FF FF 61 36 63 46 00
					39 00 00 00 00 00 27 C5 44 00 00 44 00 00 44 00 00 33 FE F7 32 72 77 11 A7 6C 11 3B 08 00 C1 00 00 00 00 00 00 00 00 00 00 00 00 00 00 00
					39 00 00 00 00 00 09 C6 44 00 00 21 00 00 00 80
					39 00 00 00 00 00 27 C7 44 00 00 33 8B 17 21 19 58 11 55 50 10 22 D8 00 99 59 00 00 00 00 00 00 00 00 00 00 00 00 00 00 00 00 00 00 00 00
					39 00 00 00 00 00 09 C8 44 00 00 32 00 00 01 00
					39 00 00 00 00 00 02 C9 30
					39 00 00 00 00 00 04 FF 5A A5 1F
					39 00 00 00 00 00 02 C0 08
					39 00 00 00 00 00 1F C2 FF FF FF AB EA FF FF FF FC FC FF FC FC FC FF FF FF FF FF FF FF FF FF FF FF FF FF FF FF FF
					39 00 00 00 00 00 04 FF 5A A5 24
					39 00 00 00 00 00 02 80 04
					39 00 00 00 00 00 02 81 8B
					39 00 00 00 00 00 02 82 0F
					39 00 00 00 00 00 02 83 FE
					39 00 00 00 00 00 02 84 00
					39 00 00 00 00 00 04 FF 5A A5 00
					39 00 00 00 00 00 02 95 FF
					39 00 00 00 00 00 02 96 09
					39 00 00 00 00 00 02 97 D9
					39 00 00 00 00 00 02 98 02
					39 00 00 00 00 00 02 99 78 //lhbm mode control end
					39 00 00 00 00 00 04 FF 5A A5 07
					39 00 00 00 00 00 02 8A 01 // PPS Enable
					39 00 00 00 00 00 03 8B 11 E0 // PPS Table
					39 00 00 00 00 00 64 80 00 00 00 00 00 12 00 00 A0 21 00 0A DC 04 F0 00 0A 02 78 02 78 01 55 01 D0 00 0A 00 89 00 35 00 0C 0A AB 31 07 08 00 0C 10 07 10 20 00 06 0F 0F 33 0E 1C 2A 38 46 54 62 69 70 77 79 7B 7D 7E 00 82 11 40 19 C0 22 3E 32 7C 3A BA 3A F8 3B 38 3B 38 3B 76 4B 76 4B 74 4B 74 5B B4 73 F4 01 00 00 00 00 00
					39 00 00 00 00 00 64 81 00 00 00 00 00 12 00 00 AB 30 80 0A DC 04 F0 00 14 02 78 02 78 02 00 02 57 00 20 01 F8 00 08 00 0D 05 7A 04 4F 18 00 10 E0 07 10 20 00 06 0F 0F 33 0E 1C 2A 38 46 54 62 69 70 77 79 7B 7D 7E 02 02 22 00 2A 40 2A BE 3A FC 3A FA 3A F8 3B 38 3B 78 3B B6 4B B6 4B F4 4B F4 6C 34 84 74 00 00 00 00 00 00
					39 00 00 00 00 00 02 91 00
					39 00 00 00 00 00 04 FF 5A A5 07
					39 00 00 00 00 00 03 8B 11 A0
					39 00 00 00 00 00 04 FF 5A A5 14
					39 00 00 00 00 00 02 82 01 // SPR IN AP ON
					39 00 00 00 00 00 04 FF 5A A5 21
					39 00 00 00 00 00 02 A4 18 // Flash reload enable
					39 00 00 00 00 00 04 FF 5A A5 13
					39 00 00 00 00 00 03 FB 18 27 // Hole related
					39 00 00 00 00 00 04 FF 5A A5 2D
					39 00 00 00 00 00 02 F2 00 // 0x00:120Hz 01:60Hz
					39 00 00 00 00 00 03 83 00 00 // 120Hz skip frame
					39 00 00 00 00 00 03 84 00 00 // 120Hz skip frame (1pulse)
					39 00 00 00 00 00 03 85 00 00 // 90Hz skip frame
					39 00 00 00 00 00 03 86 00 00 // 90Hz skip frame (1pulse)
					39 00 00 00 00 00 04 FF 5A A5 00
					39 00 00 00 00 00 02 5A 01 // ADFR
					39 00 00 00 00 00 02 5B 80 // ADFR
					39 00 00 00 00 00 04 FF 5A A5 02
					39 00 00 00 00 00 02 C0 03
					39 00 00 00 00 00 04 FF 5A A5 2D
					39 00 00 00 00 00 04 EC 01 AF 00
					39 00 00 00 00 00 03 93 A0 00
					39 00 00 00 00 00 03 94 C4 00
					39 00 00 00 00 00 03 95 00 00
					39 00 00 00 00 00 03 96 00 00
					39 00 00 00 00 00 03 ED D5 00
					39 00 00 00 00 00 04 EE 00 00 00
					/* decreasing step */
					39 00 00 00 00 00 02 97 03
					39 00 00 00 00 00 02 B1 03
					39 00 00 00 00 00 03 98 03 00
					39 00 00 00 00 00 03 99 05 00
					39 00 00 00 00 00 03 9A 0B 00
					39 00 00 00 00 00 03 9B 17 00
					39 00 00 00 00 00 03 A0 00 00
					39 00 00 00 00 00 03 A1 01 02
					39 00 00 00 00 00 02 B2 02
					39 00 00 00 00 00 02 B3 04
					39 00 00 00 00 00 02 B4 08
					39 00 00 00 00 00 02 B5 11
					39 00 00 00 00 00 03 BA 00 00
					39 00 00 00 00 00 03 BB 01 02
					39 00 00 00 00 00 04 FF 5A A5 02
					39 00 00 00 00 00 09 B0 00 80 00 10 00 00 00 00
					39 00 00 00 00 00 03 AB AF 82 // TE Left Shift 2ms
					39 00 00 00 00 00 04 FF 5A A5 31
					39 00 00 00 00 00 02 A0 A1 // CTB ON
					39 00 00 00 00 00 04 FF 5A A5 49
					39 00 00 00 00 00 02 E0 01 // ODC ON
					39 00 00 00 00 00 04 FF 5A A5 53
					39 00 00 00 00 00 03 80 0F 40 // Demura ON
					39 00 00 00 00 00 03 85 CC E1 // Loading demura data
					39 00 00 00 00 00 04 FF 5A A5 17
					39 00 00 00 00 00 02 A0 00 // RCN OFF
					/* AVEE PUMP 4H */
					39 00 00 00 00 00 04 FF 5A A5 02
					39 00 00 00 00 00 0A E5 09 0B 0B 0D 55 0D 32 32 32
					39 00 00 00 00 00 03 E7 33 25
					39 00 00 00 00 00 03 E8 33 25
					39 00 00 00 00 00 03 E9 33 25
					39 00 00 00 00 00 03 EA 33 25
					39 00 00 00 00 00 04 FF 5A A5 12
					39 00 00 00 00 00 02 81 33 // SRC keep vsp 2 frame
					39 00 00 00 00 00 04 FF 5A A5 00
					39 00 00 00 00 00 02 5E 01 // Skip frame Enable
					39 00 00 00 00 00 02 60 02 // Normal mode: 90Hz (4pulse)
					39 00 00 00 00 00 02 61 07 // AOD in mode
					39 00 00 00 00 00 02 35 00 // TE On
					39 00 00 00 00 00 02 53 20 // BC On Dimming OFF

					/* 3D LUT register */
					/* 3D LUT switch */
					39 00 00 40 00 00 04 FF 5A A5 00
					15 00 00 40 00 00 02 4D 00
					/* Gray binding points and DBV */
					39 00 00 40 00 00 04 FF 5A A5 4F
					15 00 00 40 00 00 02 91 00
					15 00 00 40 00 00 02 92 00
					15 00 00 40 00 00 02 93 08
					15 00 00 40 00 00 02 94 00
					15 00 00 40 00 00 02 95 10
					15 00 00 40 00 00 02 96 00
					15 00 00 40 00 00 02 97 20
					15 00 00 40 00 00 02 98 00
					15 00 00 40 00 00 02 99 20
					15 00 00 40 00 00 02 9A 00
					15 00 00 40 00 00 02 A0 00
					15 00 00 40 00 00 02 A1 01
					15 00 00 40 00 00 02 A2 0A
					15 00 00 40 00 00 02 A3 81
					15 00 00 40 00 00 02 A4 0F
					15 00 00 40 00 00 02 A5 FF
					/* Matrix_off && LUT3D_off && Gray2bypass */
					15 00 00 40 00 00 02 AC 0C
					/* Gamma && Degamma */
					39 00 00 40 00 00 04 FF 5A A5 13
					15 00 00 40 00 00 02 CA 70
					/* 125 point mapping value for DBV1 */
					39 00 00 40 00 00 04 FF 5A A5 70
					39 00 00 40 00 00 07 80 00 00 00 00 00 00
					39 00 00 40 00 00 07 81 00 00 00 00 09 99
					39 00 00 40 00 00 07 82 00 00 00 00 13 33
					39 00 00 40 00 00 07 83 00 00 00 00 20 04
					39 00 00 40 00 00 07 84 00 00 00 00 3F BC
					39 00 00 40 00 00 07 85 00 00 08 04 00 00
					39 00 00 40 00 00 07 86 00 00 08 04 08 04
					39 00 00 40 00 00 07 87 00 00 08 04 10 04
					39 00 00 40 00 00 07 88 00 00 08 04 20 04
					39 00 00 40 00 00 07 89 00 00 08 04 3F BC
					39 00 00 40 00 00 07 8A 00 00 10 04 00 00
					39 00 00 40 00 00 07 8B 00 00 10 04 08 04
					39 00 00 40 00 00 07 8C 00 00 10 04 10 04
					39 00 00 40 00 00 07 8D 00 00 10 04 20 04
					39 00 00 40 00 00 07 8E 00 00 10 04 3F BC
					39 00 00 40 00 00 07 8F 00 00 20 04 00 00
					39 00 00 40 00 00 07 90 00 00 20 04 08 04
					39 00 00 40 00 00 07 91 00 00 20 04 10 04
					39 00 00 40 00 00 07 92 00 00 20 04 20 04
					39 00 00 40 00 00 07 93 00 00 20 04 3F BC
					39 00 00 40 00 00 07 94 00 00 3F BC 00 00
					39 00 00 40 00 00 07 95 00 00 3F BC 08 04
					39 00 00 40 00 00 07 96 00 00 3F BC 10 04
					39 00 00 40 00 00 07 97 00 00 3F BC 20 04
					39 00 00 40 00 00 07 98 00 00 3F BC 3F BC
					39 00 00 40 00 00 07 99 04 CC 00 00 00 00
					39 00 00 40 00 00 07 9A 08 04 00 00 08 04
					39 00 00 40 00 00 07 9B 08 04 00 00 10 04
					39 00 00 40 00 00 07 9C 08 04 00 00 20 04
					39 00 00 40 00 00 07 9D 08 04 00 00 3F BC
					39 00 00 40 00 00 07 9E 08 04 08 04 00 00
					39 00 00 40 00 00 07 9F 04 CC 08 00 09 99
					39 00 00 40 00 00 07 A0 08 04 08 04 10 04
					39 00 00 40 00 00 07 A1 08 04 08 04 20 04
					39 00 00 40 00 00 07 A2 08 04 08 04 3F BC
					39 00 00 40 00 00 07 A3 08 04 10 04 00 00
					39 00 00 40 00 00 07 A4 08 04 10 04 08 04
					39 00 00 40 00 00 07 A5 08 04 10 04 10 04
					39 00 00 40 00 00 07 A6 08 04 10 04 20 04
					39 00 00 40 00 00 07 A7 08 04 10 04 3F BC
					39 00 00 40 00 00 07 A8 08 04 20 04 00 00
					39 00 00 40 00 00 07 A9 08 04 20 04 08 04
					39 00 00 40 00 00 07 AA 08 04 20 04 10 04
					39 00 00 40 00 00 07 AB 08 04 20 04 20 04
					39 00 00 40 00 00 07 AC 08 04 20 04 3F BC
					39 00 00 40 00 00 07 AD 08 04 3F BC 00 00
					39 00 00 40 00 00 07 AE 08 04 3F BC 08 04
					39 00 00 40 00 00 07 AF 08 04 3F BC 10 04
					39 00 00 40 00 00 07 B0 08 04 3F BC 20 04
					39 00 00 40 00 00 07 B1 08 04 3F BC 3F BC
					39 00 00 40 00 00 07 B2 09 99 00 00 00 00
					39 00 00 40 00 00 07 B3 10 04 00 00 08 04
					39 00 00 40 00 00 07 B4 10 04 00 00 10 04
					39 00 00 40 00 00 07 B5 10 04 00 00 20 04
					39 00 00 40 00 00 07 B6 10 04 00 00 3F BC
					39 00 00 40 00 00 07 B7 10 04 08 04 00 00
					39 00 00 40 00 00 07 B8 10 04 08 04 08 04
					39 00 00 40 00 00 07 B9 10 04 08 04 10 04
					39 00 00 40 00 00 07 BA 10 04 08 04 20 04
					39 00 00 40 00 00 07 BB 10 04 08 04 3F BC
					39 00 00 40 00 00 07 BC 10 04 10 04 00 00
					39 00 00 40 00 00 07 BD 10 04 10 04 08 04
					39 00 00 40 00 00 07 BE 09 99 10 04 13 33
					39 00 00 40 00 00 07 BF 10 04 10 04 20 04
					39 00 00 40 00 00 07 C0 10 04 10 04 3F BC
					39 00 00 40 00 00 07 C1 10 04 20 04 00 00
					39 00 00 40 00 00 07 C2 10 04 20 04 08 04
					39 00 00 40 00 00 07 C3 10 04 20 04 10 04
					39 00 00 40 00 00 07 C4 10 04 20 04 20 04
					39 00 00 40 00 00 07 C5 10 04 20 04 3F BC
					39 00 00 40 00 00 07 C6 10 04 3F BC 00 00
					39 00 00 40 00 00 07 C7 10 04 3F BC 08 04
					39 00 00 40 00 00 07 C8 10 04 3F BC 10 04
					39 00 00 40 00 00 07 C9 10 04 3F BC 20 04
					39 00 00 40 00 00 07 CA 10 04 3F BC 3F BC
					39 00 00 40 00 00 07 CB 20 04 00 00 00 00
					39 00 00 40 00 00 07 CC 20 04 00 00 08 04
					39 00 00 40 00 00 07 CD 20 04 00 00 10 04
					39 00 00 40 00 00 07 CE 20 04 00 00 20 04
					39 00 00 40 00 00 07 CF 20 04 00 00 3F BC
					39 00 00 40 00 00 07 D0 20 04 08 04 00 00
					39 00 00 40 00 00 07 D1 20 04 08 04 08 04
					39 00 00 40 00 00 07 D2 20 04 08 04 10 04
					39 00 00 40 00 00 07 D3 20 04 08 04 20 04
					39 00 00 40 00 00 07 D4 20 04 08 04 3F BC
					39 00 00 40 00 00 07 D5 20 04 10 04 00 00
					39 00 00 40 00 00 07 D6 20 04 10 04 08 04
					39 00 00 40 00 00 07 D7 20 04 10 04 10 04
					39 00 00 40 00 00 07 D8 20 04 10 04 20 04
					39 00 00 40 00 00 07 D9 20 04 10 04 3F BC
					39 00 00 40 00 00 07 DA 20 04 20 04 00 00
					39 00 00 40 00 00 07 DB 20 04 20 04 08 04
					39 00 00 40 00 00 07 DC 20 04 20 04 10 04
					39 00 00 40 00 00 07 DD 20 00 20 00 20 00
					39 00 00 40 00 00 07 DE 20 04 20 04 3F BC
					39 00 00 40 00 00 07 DF 20 04 3F BC 00 00
					39 00 00 40 00 00 07 E0 20 04 3F BC 08 04
					39 00 00 40 00 00 07 E1 20 04 3F BC 10 04
					39 00 00 40 00 00 07 E2 20 04 3F BC 20 04
					39 00 00 40 00 00 07 E3 20 04 3F BC 3F BC
					39 00 00 40 00 00 07 E4 3F BC 00 00 00 00
					39 00 00 40 00 00 07 E5 3F BC 00 00 08 04
					39 00 00 40 00 00 07 E6 3F BC 00 00 10 04
					39 00 00 40 00 00 07 E7 3F BC 00 00 20 04
					39 00 00 40 00 00 07 E8 3F BC 00 00 3F BC
					39 00 00 40 00 00 07 E9 3F BC 08 04 00 00
					39 00 00 40 00 00 07 EA 3F BC 08 04 08 04
					39 00 00 40 00 00 07 EB 3F BC 08 04 10 04
					39 00 00 40 00 00 07 EC 3F BC 08 04 20 04
					39 00 00 40 00 00 07 ED 3F BC 08 04 3F BC
					39 00 00 40 00 00 07 EE 3F BC 10 04 00 00
					39 00 00 40 00 00 07 EF 3F BC 10 04 08 04
					39 00 00 40 00 00 07 F0 3F BC 10 04 10 04
					39 00 00 40 00 00 07 F1 3F BC 10 04 20 04
					39 00 00 40 00 00 07 F2 3F BC 10 04 3F BC
					39 00 00 40 00 00 07 F3 3F BC 20 04 00 00
					39 00 00 40 00 00 07 F4 3F BC 20 04 08 04
					39 00 00 40 00 00 07 F5 3F BC 20 04 10 04
					39 00 00 40 00 00 07 F6 3F BC 20 04 20 04
					39 00 00 40 00 00 07 F7 3F BC 20 04 3F BC
					39 00 00 40 00 00 07 F8 3F BC 3F BC 00 00
					39 00 00 40 00 00 07 F9 3F BC 3F BC 08 04
					39 00 00 40 00 00 07 FA 3F BC 3F BC 10 04
					39 00 00 40 00 00 07 FB 3F BC 3F BC 20 04
					39 00 00 40 00 00 07 FC 3F C0 3F C0 3F C0
					/* 125 point mapping value for DBV2 */
					39 00 00 40 00 00 04 FF 5A A5 71
					39 00 00 40 00 00 07 80 00 00 00 00 00 00
					39 00 00 40 00 00 07 81 00 00 00 00 09 99
					39 00 00 40 00 00 07 82 00 00 00 00 13 33
					39 00 00 40 00 00 07 83 00 00 00 00 20 04
					39 00 00 40 00 00 07 84 00 00 00 00 3F BC
					39 00 00 40 00 00 07 85 00 00 08 04 00 00
					39 00 00 40 00 00 07 86 00 00 08 04 08 04
					39 00 00 40 00 00 07 87 00 00 08 04 10 04
					39 00 00 40 00 00 07 88 00 00 08 04 20 04
					39 00 00 40 00 00 07 89 00 00 08 04 3F BC
					39 00 00 40 00 00 07 8A 00 00 10 04 00 00
					39 00 00 40 00 00 07 8B 00 00 10 04 08 04
					39 00 00 40 00 00 07 8C 00 00 10 04 10 04
					39 00 00 40 00 00 07 8D 00 00 10 04 20 04
					39 00 00 40 00 00 07 8E 00 00 10 04 3F BC
					39 00 00 40 00 00 07 8F 00 00 20 04 00 00
					39 00 00 40 00 00 07 90 00 00 20 04 08 04
					39 00 00 40 00 00 07 91 00 00 20 04 10 04
					39 00 00 40 00 00 07 92 00 00 20 04 20 04
					39 00 00 40 00 00 07 93 00 00 20 04 3F BC
					39 00 00 40 00 00 07 94 00 00 3F BC 00 00
					39 00 00 40 00 00 07 95 00 00 3F BC 08 04
					39 00 00 40 00 00 07 96 00 00 3F BC 10 04
					39 00 00 40 00 00 07 97 00 00 3F BC 20 04
					39 00 00 40 00 00 07 98 00 00 3F BC 3F BC
					39 00 00 40 00 00 07 99 04 CC 00 00 00 00
					39 00 00 40 00 00 07 9A 08 04 00 00 08 04
					39 00 00 40 00 00 07 9B 08 04 00 00 10 04
					39 00 00 40 00 00 07 9C 08 04 00 00 20 04
					39 00 00 40 00 00 07 9D 08 04 00 00 3F BC
					39 00 00 40 00 00 07 9E 08 04 08 04 00 00
					39 00 00 40 00 00 07 9F 04 CC 08 00 09 99
					39 00 00 40 00 00 07 A0 08 04 08 04 10 04
					39 00 00 40 00 00 07 A1 08 04 08 04 20 04
					39 00 00 40 00 00 07 A2 08 04 08 04 3F BC
					39 00 00 40 00 00 07 A3 08 04 10 04 00 00
					39 00 00 40 00 00 07 A4 08 04 10 04 08 04
					39 00 00 40 00 00 07 A5 08 04 10 04 10 04
					39 00 00 40 00 00 07 A6 08 04 10 04 20 04
					39 00 00 40 00 00 07 A7 08 04 10 04 3F BC
					39 00 00 40 00 00 07 A8 08 04 20 04 00 00
					39 00 00 40 00 00 07 A9 08 04 20 04 08 04
					39 00 00 40 00 00 07 AA 08 04 20 04 10 04
					39 00 00 40 00 00 07 AB 08 04 20 04 20 04
					39 00 00 40 00 00 07 AC 08 04 20 04 3F BC
					39 00 00 40 00 00 07 AD 08 04 3F BC 00 00
					39 00 00 40 00 00 07 AE 08 04 3F BC 08 04
					39 00 00 40 00 00 07 AF 08 04 3F BC 10 04
					39 00 00 40 00 00 07 B0 08 04 3F BC 20 04
					39 00 00 40 00 00 07 B1 08 04 3F BC 3F BC
					39 00 00 40 00 00 07 B2 09 99 00 00 00 00
					39 00 00 40 00 00 07 B3 10 04 00 00 08 04
					39 00 00 40 00 00 07 B4 10 04 00 00 10 04
					39 00 00 40 00 00 07 B5 10 04 00 00 20 04
					39 00 00 40 00 00 07 B6 10 04 00 00 3F BC
					39 00 00 40 00 00 07 B7 10 04 08 04 00 00
					39 00 00 40 00 00 07 B8 10 04 08 04 08 04
					39 00 00 40 00 00 07 B9 10 04 08 04 10 04
					39 00 00 40 00 00 07 BA 10 04 08 04 20 04
					39 00 00 40 00 00 07 BB 10 04 08 04 3F BC
					39 00 00 40 00 00 07 BC 10 04 10 04 00 00
					39 00 00 40 00 00 07 BD 10 04 10 04 08 04
					39 00 00 40 00 00 07 BE 09 99 10 04 13 33
					39 00 00 40 00 00 07 BF 10 04 10 04 20 04
					39 00 00 40 00 00 07 C0 10 04 10 04 3F BC
					39 00 00 40 00 00 07 C1 10 04 20 04 00 00
					39 00 00 40 00 00 07 C2 10 04 20 04 08 04
					39 00 00 40 00 00 07 C3 10 04 20 04 10 04
					39 00 00 40 00 00 07 C4 10 04 20 04 20 04
					39 00 00 40 00 00 07 C5 10 04 20 04 3F BC
					39 00 00 40 00 00 07 C6 10 04 3F BC 00 00
					39 00 00 40 00 00 07 C7 10 04 3F BC 08 04
					39 00 00 40 00 00 07 C8 10 04 3F BC 10 04
					39 00 00 40 00 00 07 C9 10 04 3F BC 20 04
					39 00 00 40 00 00 07 CA 10 04 3F BC 3F BC
					39 00 00 40 00 00 07 CB 20 04 00 00 00 00
					39 00 00 40 00 00 07 CC 20 04 00 00 08 04
					39 00 00 40 00 00 07 CD 20 04 00 00 10 04
					39 00 00 40 00 00 07 CE 20 04 00 00 20 04
					39 00 00 40 00 00 07 CF 20 04 00 00 3F BC
					39 00 00 40 00 00 07 D0 20 04 08 04 00 00
					39 00 00 40 00 00 07 D1 20 04 08 04 08 04
					39 00 00 40 00 00 07 D2 20 04 08 04 10 04
					39 00 00 40 00 00 07 D3 20 04 08 04 20 04
					39 00 00 40 00 00 07 D4 20 04 08 04 3F BC
					39 00 00 40 00 00 07 D5 20 04 10 04 00 00
					39 00 00 40 00 00 07 D6 20 04 10 04 08 04
					39 00 00 40 00 00 07 D7 20 04 10 04 10 04
					39 00 00 40 00 00 07 D8 20 04 10 04 20 04
					39 00 00 40 00 00 07 D9 20 04 10 04 3F BC
					39 00 00 40 00 00 07 DA 20 04 20 04 00 00
					39 00 00 40 00 00 07 DB 20 04 20 04 08 04
					39 00 00 40 00 00 07 DC 20 04 20 04 10 04
					39 00 00 40 00 00 07 DD 20 00 20 00 20 00
					39 00 00 40 00 00 07 DE 20 04 20 04 3F BC
					39 00 00 40 00 00 07 DF 20 04 3F BC 00 00
					39 00 00 40 00 00 07 E0 20 04 3F BC 08 04
					39 00 00 40 00 00 07 E1 20 04 3F BC 10 04
					39 00 00 40 00 00 07 E2 20 04 3F BC 20 04
					39 00 00 40 00 00 07 E3 20 04 3F BC 3F BC
					39 00 00 40 00 00 07 E4 3F BC 00 00 00 00
					39 00 00 40 00 00 07 E5 3F BC 00 00 08 04
					39 00 00 40 00 00 07 E6 3F BC 00 00 10 04
					39 00 00 40 00 00 07 E7 3F BC 00 00 20 04
					39 00 00 40 00 00 07 E8 3F BC 00 00 3F BC
					39 00 00 00 00 00 07 E9 3F BC 08 04 00 00
					39 00 00 40 00 00 07 EA 3F BC 08 04 08 04
					39 00 00 40 00 00 07 EB 3F BC 08 04 10 04
					39 00 00 40 00 00 07 EC 3F BC 08 04 20 04
					39 00 00 40 00 00 07 ED 3F BC 08 04 3F BC
					39 00 00 40 00 00 07 EE 3F BC 10 04 00 00
					39 00 00 40 00 00 07 EF 3F BC 10 04 08 04
					39 00 00 40 00 00 07 F0 3F BC 10 04 10 04
					39 00 00 40 00 00 07 F1 3F BC 10 04 20 04
					39 00 00 40 00 00 07 F2 3F BC 10 04 3F BC
					39 00 00 40 00 00 07 F3 3F BC 20 04 00 00
					39 00 00 40 00 00 07 F4 3F BC 20 04 08 04
					39 00 00 40 00 00 07 F5 3F BC 20 04 10 04
					39 00 00 40 00 00 07 F6 3F BC 20 04 20 04
					39 00 00 40 00 00 07 F7 3F BC 20 04 3F BC
					39 00 00 40 00 00 07 F8 3F BC 3F BC 00 00
					39 00 00 40 00 00 07 F9 3F BC 3F BC 08 04
					39 00 00 40 00 00 07 FA 3F BC 3F BC 10 04
					39 00 00 40 00 00 07 FB 3F BC 3F BC 20 04
					39 00 00 00 00 00 07 FC 3F C0 3F C0 3F C0

					05 00 00 00 78 00 01 11 // Sleep OUT
					/* TE raise */
					39 00 00 00 00 00 04 FF 5A A5 22
					39 00 00 00 00 00 08 D8 00 DB 11 10 32 14 14
					39 00 00 00 00 00 08 D9 00 DB 11 10 32 14 14
					39 00 00 00 00 00 08 DA 00 DB 11 10 32 14 14
					39 00 00 00 00 00 08 DB 00 DB 11 10 32 14 14
					39 00 00 00 00 00 0A DC 84 94 BB 00 20 C4 A1 CC 10
					39 00 00 00 00 00 02 DD 01
					39 00 00 00 00 00 02 DE F1
					39 00 00 00 00 00 02 DF 80
					39 00 00 00 00 00 08 E0 02 00 5F 21 00 28 00
					39 00 00 00 00 00 04 FF 5A A5 00
					39 00 00 00 00 00 01 29 // Display ON
				];
				oplus,dsi-aod-off-command = [
					39 00 00 40 00 00 04 FF 5A A5 02
					39 00 00 40 00 00 03 AB AF 82 //TE Shift ON
					39 00 00 40 00 00 03 88 C0 00
					39 00 00 40 00 00 04 FF 5A A5 00
					39 00 00 40 00 00 02 38 00
					39 00 00 00 00 00 05 51 00 00 00 00
				];
				oplus,dsi-ultra-low-power-aod-on-command = [
					39 00 00 40 00 00 04 FF 5A A5 2D
					39 00 00 40 00 00 03 8A 1D 00
					39 00 00 00 00 00 04 FF 5A A5 00
				];
				oplus,dsi-ultra-low-power-aod-off-command = [
					39 00 00 40 00 00 04 FF 5A A5 2D
					39 00 00 40 00 00 03 8A 00 00
					39 00 00 00 00 00 04 FF 5A A5 00
				];
				oplus,dsi-hbm-on-command = [
					39 00 00 00 00 00 03 51 0E E0
				];
				oplus,dsi-hbm-off-command = [
					39 00 00 00 00 00 03 51 0D BB
				];
				oplus,dsi-adfr-min-fps-90hz-command = [
					39 00 00 40 00 00 04 FF 5A A5 2D
					39 00 00 40 00 00 03 85 00 00
					39 00 00 40 00 00 03 86 00 00
					39 00 00 00 00 00 04 FF 5A A5 00
				];
				oplus,dsi-adfr-min-fps-45hz-command = [
					39 00 00 40 00 00 04 FF 5A A5 2D
					39 00 00 40 00 00 03 85 01 00
					39 00 00 40 00 00 03 86 01 00
					39 00 00 00 00 00 04 FF 5A A5 00
				];
				oplus,dsi-adfr-min-fps-30hz-command = [
					39 00 00 40 00 00 04 FF 5A A5 2D
					39 00 00 40 00 00 03 85 02 00
					39 00 00 40 00 00 03 86 02 00
					39 00 00 00 00 00 04 FF 5A A5 00
				];
				oplus,dsi-adfr-min-fps-15hz-command = [
					39 00 00 40 00 00 04 FF 5A A5 2D
					39 00 00 40 00 00 03 85 05 00
					39 00 00 40 00 00 03 86 05 00
					39 00 00 00 00 00 04 FF 5A A5 00
				];
				oplus,dsi-adfr-min-fps-10hz-command = [
					39 00 00 40 00 00 04 FF 5A A5 2D
					39 00 00 40 00 00 03 85 08 00
					39 00 00 40 00 00 03 86 08 00
					39 00 00 00 00 00 04 FF 5A A5 00
				];
				oplus,dsi-adfr-min-fps-5hz-command = [
					39 00 00 40 00 00 04 FF 5A A5 2D
					39 00 00 40 00 00 03 85 11 00
					39 00 00 40 00 00 03 86 11 00
					39 00 00 00 00 00 04 FF 5A A5 00
				];
				oplus,dsi-adfr-min-fps-1hz-command = [
					39 00 00 40 00 00 04 FF 5A A5 2D
					39 00 00 40 00 00 03 85 59 00
					39 00 00 40 00 00 03 86 59 00
					39 00 00 00 00 00 04 FF 5A A5 00
				];
				oplus,dsi-pwm-switch-1to3pul-command = [
					39 00 00 40 00 00 04 FF 5A A5 53
					39 00 00 40 00 00 03 85 CC E1 // Normal Demura
					39 00 00 40 00 00 04 FF 5A A5 00
					39 00 00 00 00 00 02 60 02
				];
				oplus,dsi-pwm-switch-3to1pul-command = [
					39 00 00 40 00 00 04 FF 5A A5 53
					39 00 00 40 00 00 03 85 CC E3 // DC Demura
					39 00 00 40 00 00 04 FF 5A A5 00
					39 00 00 00 00 00 02 60 03
				];

				oplus,dsi-timing-switch-command-state = "dsi_hs_mode";
				oplus,dsi-timing-switch-1pulse-command-state = "dsi_hs_mode";
				oplus,dsi-on-command-state = "dsi_lp_mode";
				oplus,dsi-aod-off-command-state = "dsi_ls_mode";
				oplus,dsi-ultra-low-power-aod-off-command-state = "dsi_ls_mode";
				oplus,dsi-ultra-low-power-aod-on-command-state = "dsi_ls_mode";
				oplus,dsi-hbm-on-command-state = "dsi_hs_mode";
				oplus,dsi-hbm-off-command-state = "dsi_hs_mode";
				oplus,dsi-auto-off-minfps-command-state = "dsi_hs_mode";
				oplus,dsi-pwm-switch-1to3pul-command-state = "dsi_hs_mode";
				oplus,dsi-pwm-switch-3to1pul-command-state = "dsi_hs_mode";
				oplus,dsi-adfr-min-fps-90hz-command-state = "dsi_hs_mode";
				oplus,dsi-adfr-min-fps-45hz-command-state = "dsi_hs_mode";
				oplus,dsi-adfr-min-fps-30hz-command-state = "dsi_hs_mode";
				oplus,dsi-adfr-min-fps-15hz-command-state = "dsi_hs_mode";
				oplus,dsi-adfr-min-fps-10hz-command-state = "dsi_hs_mode";
				oplus,dsi-adfr-min-fps-5hz-command-state = "dsi_hs_mode";
				oplus,dsi-adfr-min-fps-1hz-command-state = "dsi_hs_mode";
				oplus,dsc-params-entries = <&dsc_params>;
				oplus,spr-params-entries = <&spr_params>;
				oplus,phy-timcon {
					hs-trail = <14>;
					clk-trail = <15>;
				};
				oplus,dyn-fps {
					switch_en = <1>;
					vact_timing_fps = <90>;
					apollo_limit_superior_us = <7880>;
					apollo_limit_inferior_us = <10000>;
					apollo_transfer_time_us = <8800>;
				};
				oplus,display-mode {
					display-mode@0 {
						hdisplay = <1264>;
						vdisplay = <2780>;
						fhd-hfp = <9>;
						fhd-hsa = <2>;
						fhd-hbp = <21>;
						fhd-vfp = <52>;
						fhd-vsa = <14>;
						fhd-vbp = <22>;
						hskew = <0>;
					};
					display-mode@1 {
						hdisplay = <1080>;
						vdisplay = <2376>;
						fhd-hfp = <9>;
						fhd-hsa = <2>;
						fhd-hbp = <21>;
						fhd-vfp = <66>;
						fhd-vsa = <24>;
						fhd-vbp = <36>;
						hskew = <0>;
					};
				};
			};
			timing@sa_fhd_120 {
				cell-index = <2>;
				oplus,dsi-panel-framerate = <120>;
				oplus,dsi-panel-pllclk = <556>;
				oplus,is-support-dmr;
				oplus,cmd-null-pkt-en = <0>;
				oplus,cmd-null-pkt-len = <0>;
				oplus,merge-trig-offset = <333>;
				oplus,vidle-te-duration = <7900>;
				/* OPLUS_FEATURE_DISPLAY_ONSCREENFINGERPRINT */
				oplus,ofp_need_keep_apart_backlight;
				oplus,ofp-hbm-on-delay = <0>;
				oplus,ofp-pre-hbm-off-delay = <6>;
				oplus,ofp-hbm-off-delay = <0>;
				oplus,ofp-need-to-sync-data-in-aod-unlocking;
				oplus,ofp-aod-off-insert-black = <2>;
				oplus,ofp-aod-off-black-frame-total-time = <42>;
				#include "panel-ac180-p-3-a0020-dsi-cmd-common-T0.dtsi"
				oplus,dsi-timing-switch-command = [
					39 00 00 40 00 00 04 FF 5A A5 00
					39 00 00 40 00 00 02 60 00 // 0x00: 120Hz 02: 90Hz
					39 00 00 40 00 00 04 FF 5A A5 53
					39 00 00 40 00 00 03 85 CC E1 // Normal Demura
					39 00 00 40 00 00 04 FF 5A A5 2D
					39 00 00 40 00 00 03 83 00 00
					39 00 00 40 00 00 02 F2 00
					39 00 00 00 00 00 04 FF 5A A5 00
				];
				oplus,dsi-timing-switch-1pulse-command = [
					39 00 00 40 00 00 04 FF 5A A5 00
					39 00 00 40 00 00 02 60 01 // 0x01: 120Hz 03: 90Hz
					39 00 00 40 00 00 04 FF 5A A5 53
					39 00 00 40 00 00 03 85 CC E3 // DC Demura
					39 00 00 40 00 00 04 FF 5A A5 2D
					39 00 00 40 00 00 03 84 00 00
					39 00 00 40 00 00 02 F2 00
					39 00 00 00 00 00 04 FF 5A A5 00
				];
				oplus,dsi-on-command = [
					39 00 00 00 00 00 04 FF 5A A5 08
					39 00 00 00 00 00 02 C8 62 // Sleep out don't reload
					39 00 00 00 00 00 04 FF 5A A5 10 //lhbm mode control begin
					39 00 00 00 00 00 27 8F C8 7C 00 42 00 80 10 00 5A 00 59 58 00 40 1F 00 0D 08 00 05 03 00 02 00 00 00 00 00 00 00 00 00 00 00 00 00 00 00
					39 00 00 00 00 00 04 FF 5A A5 24
					39 00 00 00 00 00 09 A5 0F FF 0F FE 0D BB 0B 1A
					39 00 00 00 00 00 09 A6 07 52 04 8B 04 8A 04 76
					39 00 00 00 00 00 09 A7 03 E6 02 CB 01 E1 01 7D
					39 00 00 00 00 00 09 A8 01 19 00 B5 00 01 00 00
					39 00 00 00 00 00 09 A9 00 00 00 00 00 00 00 00
					39 00 00 00 00 00 09 AA 00 00 00 00 00 00 00 00
					39 00 00 00 00 00 03 AB 00 00
					39 00 00 00 00 00 04 FF 5A A5 29
					39 00 00 00 00 00 09 93 0F FF 0F FE 0D BB 0B 1A
					39 00 00 00 00 00 09 94 07 52 04 8B 04 8A 04 76
					39 00 00 00 00 00 09 95 03 E6 02 CB 01 E1 01 7D
					39 00 00 00 00 00 09 96 01 19 00 B5 00 01 00 00
					39 00 00 00 00 00 09 97 00 00 00 00 00 00 00 00
					39 00 00 00 00 00 09 98 00 00 00 00 00 00 00 00
					39 00 00 00 00 00 09 99 00 00 00 00 00 00 00 00
					39 00 00 00 00 00 05 9A 00 00 00 00
					39 00 00 00 00 00 04 FF 5A A5 00
					39 00 00 00 00 00 02 4F 31
					39 00 00 00 00 00 04 FF 5A A5 1E
					39 00 00 00 00 00 02 80 89
					39 00 00 00 00 00 02 85 10
					39 00 00 00 00 00 02 9A 3F
					39 00 00 00 00 00 02 9B 01
					39 00 00 00 00 00 18 94 00 00 23 00 68 CF 12 58 03 23 D0 BF 46 D0 03 78 58 CF AC 68 23 0E 00
					39 00 00 00 00 00 19 95 00 00 12 00 46 9C 11 14 AE 23 6A 48 45 48 6A 68 AE 14 9B 9C 46 DF 12 00
					39 00 00 00 00 00 0D 96 FD F3 E6 CD B3 9A 80 66 4D 33 1A 00
					39 00 00 00 00 00 13 97 00 29 CC 13 98 30 46 C8 60 79 F8 90 BC 28 C0 EF 58 F0
					39 00 00 00 00 00 04 FF 5A A5 1F
					39 00 00 00 00 00 02 C0 08
					39 00 00 00 00 00 04 FF 5A A5 00
					39 00 00 00 00 00 02 6E 00
					39 00 00 00 00 00 04 FF 5A A5 1E
					39 00 00 00 00 00 02 C0 10
					39 00 00 00 00 00 04 C1 70 9C C1
					39 00 00 00 00 00 09 C2 FF FF FF 61 36 63 46 00
					39 00 00 00 00 00 27 C5 44 00 00 44 00 00 44 00 00 33 FE F7 32 72 77 11 A7 6C 11 3B 08 00 C1 00 00 00 00 00 00 00 00 00 00 00 00 00 00 00
					39 00 00 00 00 00 09 C6 44 00 00 21 00 00 00 80
					39 00 00 00 00 00 27 C7 44 00 00 33 8B 17 21 19 58 11 55 50 10 22 D8 00 99 59 00 00 00 00 00 00 00 00 00 00 00 00 00 00 00 00 00 00 00 00
					39 00 00 00 00 00 09 C8 44 00 00 32 00 00 01 00
					39 00 00 00 00 00 02 C9 30
					39 00 00 00 00 00 04 FF 5A A5 1F
					39 00 00 00 00 00 02 C0 08
					39 00 00 00 00 00 1F C2 FF FF FF AB EA FF FF FF FC FC FF FC FC FC FF FF FF FF FF FF FF FF FF FF FF FF FF FF FF FF
					39 00 00 00 00 00 04 FF 5A A5 24
					39 00 00 00 00 00 02 80 04
					39 00 00 00 00 00 02 81 8B
					39 00 00 00 00 00 02 82 0F
					39 00 00 00 00 00 02 83 FE
					39 00 00 00 00 00 02 84 00
					39 00 00 00 00 00 04 FF 5A A5 00
					39 00 00 00 00 00 02 95 FF
					39 00 00 00 00 00 02 96 09
					39 00 00 00 00 00 02 97 D9
					39 00 00 00 00 00 02 98 02
					39 00 00 00 00 00 02 99 78 //lhbm mode control end
					39 00 00 00 00 00 04 FF 5A A5 07
					39 00 00 00 00 00 02 8A 01 // PPS Enable
					39 00 00 00 00 00 03 8B 11 E0 // PPS Table
					39 00 00 00 00 00 64 80 00 00 00 00 00 12 00 00 A0 21 00 0A DC 04 F0 00 0A 02 78 02 78 01 55 01 D0 00 0A 00 89 00 35 00 0C 0A AB 31 07 08 00 0C 10 07 10 20 00 06 0F 0F 33 0E 1C 2A 38 46 54 62 69 70 77 79 7B 7D 7E 00 82 11 40 19 C0 22 3E 32 7C 3A BA 3A F8 3B 38 3B 38 3B 76 4B 76 4B 74 4B 74 5B B4 73 F4 01 00 00 00 00 00
					39 00 00 00 00 00 64 81 00 00 00 00 00 12 00 00 AB 30 80 0A DC 04 F0 00 14 02 78 02 78 02 00 02 57 00 20 01 F8 00 08 00 0D 05 7A 04 4F 18 00 10 E0 07 10 20 00 06 0F 0F 33 0E 1C 2A 38 46 54 62 69 70 77 79 7B 7D 7E 02 02 22 00 2A 40 2A BE 3A FC 3A FA 3A F8 3B 38 3B 78 3B B6 4B B6 4B F4 4B F4 6C 34 84 74 00 00 00 00 00 00
					39 00 00 00 00 00 02 91 00
					39 00 00 00 00 00 04 FF 5A A5 07
					39 00 00 00 00 00 03 8B 11 A0
					39 00 00 00 00 00 04 FF 5A A5 14
					39 00 00 00 00 00 02 82 01 // SPR IN AP ON
					39 00 00 00 00 00 04 FF 5A A5 21
					39 00 00 00 00 00 02 A4 18 // Flash reload enable
					39 00 00 00 00 00 04 FF 5A A5 13
					39 00 00 00 00 00 03 FB 18 27 // Hole related
					39 00 00 00 00 00 04 FF 5A A5 2D
					39 00 00 00 00 00 02 F2 00 // 0x00:120Hz 01:60Hz
					39 00 00 00 00 00 03 83 00 00 // 120Hz skip frame
					39 00 00 00 00 00 03 84 00 00 // 120Hz skip frame (1pulse)
					39 00 00 00 00 00 03 85 00 00 // 90Hz skip frame
					39 00 00 00 00 00 03 86 00 00 // 90Hz skip frame (1pulse)
					39 00 00 00 00 00 04 FF 5A A5 00
					39 00 00 00 00 00 02 5A 01 // ADFR
					39 00 00 00 00 00 02 5B 80 // ADFR
					39 00 00 00 00 00 04 FF 5A A5 02
					39 00 00 00 00 00 02 C0 03
					39 00 00 00 00 00 04 FF 5A A5 2D
					39 00 00 00 00 00 04 EC 01 AF 00
					39 00 00 00 00 00 03 93 A0 00
					39 00 00 00 00 00 03 94 C4 00
					39 00 00 00 00 00 03 95 00 00
					39 00 00 00 00 00 03 96 00 00
					39 00 00 00 00 00 03 ED D5 00
					39 00 00 00 00 00 04 EE 00 00 00
					/* decreasing step */
					39 00 00 00 00 00 02 97 03
					39 00 00 00 00 00 02 B1 03
					39 00 00 00 00 00 03 98 03 00
					39 00 00 00 00 00 03 99 05 00
					39 00 00 00 00 00 03 9A 0B 00
					39 00 00 00 00 00 03 9B 17 00
					39 00 00 00 00 00 03 A0 00 00
					39 00 00 00 00 00 03 A1 01 02
					39 00 00 00 00 00 02 B2 02
					39 00 00 00 00 00 02 B3 04
					39 00 00 00 00 00 02 B4 08
					39 00 00 00 00 00 02 B5 11
					39 00 00 00 00 00 03 BA 00 00
					39 00 00 00 00 00 03 BB 01 02
					39 00 00 00 00 00 04 FF 5A A5 02
					39 00 00 00 00 00 09 B0 00 80 00 10 00 00 00 00
					39 00 00 00 00 00 03 AB AF 82 // TE Left Shift 2ms
					39 00 00 00 00 00 04 FF 5A A5 31
					39 00 00 00 00 00 02 A0 A1 // CTB ON
					39 00 00 00 00 00 04 FF 5A A5 49
					39 00 00 00 00 00 02 E0 01 // ODC ON
					39 00 00 00 00 00 04 FF 5A A5 53
					39 00 00 00 00 00 03 80 0F 40 // Demura ON
					39 00 00 00 00 00 03 85 CC E1 // Loading demura data
					39 00 00 00 00 00 04 FF 5A A5 17
					39 00 00 00 00 00 02 A0 00 // RCN OFF
					/* AVEE PUMP 4H */
					39 00 00 00 00 00 04 FF 5A A5 02
					39 00 00 00 00 00 0A E5 09 0B 0B 0D 55 0D 32 32 32
					39 00 00 00 00 00 03 E7 33 25
					39 00 00 00 00 00 03 E8 33 25
					39 00 00 00 00 00 03 E9 33 25
					39 00 00 00 00 00 03 EA 33 25
					39 00 00 00 00 00 04 FF 5A A5 12
					39 00 00 00 00 00 02 81 33 // SRC keep vsp 2 frame
					39 00 00 00 00 00 04 FF 5A A5 00
					39 00 00 00 00 00 02 5E 01 // Skip frame Enable
					39 00 00 00 00 00 02 60 00 // Normal mode: 120Hz (3pulse)
					39 00 00 00 00 00 02 61 07 // AOD in mode
					39 00 00 00 00 00 02 35 00 // TE On
					39 00 00 00 00 00 02 53 20 // BC On Dimming OFF

					/* 3D LUT register */
					/* 3D LUT switch */
					39 00 00 40 00 00 04 FF 5A A5 00
					15 00 00 40 00 00 02 4D 00
					/* Gray binding points and DBV */
					39 00 00 40 00 00 04 FF 5A A5 4F
					15 00 00 40 00 00 02 91 00
					15 00 00 40 00 00 02 92 00
					15 00 00 40 00 00 02 93 08
					15 00 00 40 00 00 02 94 00
					15 00 00 40 00 00 02 95 10
					15 00 00 40 00 00 02 96 00
					15 00 00 40 00 00 02 97 20
					15 00 00 40 00 00 02 98 00
					15 00 00 40 00 00 02 99 20
					15 00 00 40 00 00 02 9A 00
					15 00 00 40 00 00 02 A0 00
					15 00 00 40 00 00 02 A1 01
					15 00 00 40 00 00 02 A2 0A
					15 00 00 40 00 00 02 A3 81
					15 00 00 40 00 00 02 A4 0F
					15 00 00 40 00 00 02 A5 FF
					/* Matrix_off && LUT3D_off && Gray2bypass */
					15 00 00 40 00 00 02 AC 0C
					/* Gamma && Degamma */
					39 00 00 40 00 00 04 FF 5A A5 13
					15 00 00 40 00 00 02 CA 70
					/* 125 point mapping value for DBV1 */
					39 00 00 40 00 00 04 FF 5A A5 70
					39 00 00 40 00 00 07 80 00 00 00 00 00 00
					39 00 00 40 00 00 07 81 00 00 00 00 09 99
					39 00 00 40 00 00 07 82 00 00 00 00 13 33
					39 00 00 40 00 00 07 83 00 00 00 00 20 04
					39 00 00 40 00 00 07 84 00 00 00 00 3F BC
					39 00 00 40 00 00 07 85 00 00 08 04 00 00
					39 00 00 40 00 00 07 86 00 00 08 04 08 04
					39 00 00 40 00 00 07 87 00 00 08 04 10 04
					39 00 00 40 00 00 07 88 00 00 08 04 20 04
					39 00 00 40 00 00 07 89 00 00 08 04 3F BC
					39 00 00 40 00 00 07 8A 00 00 10 04 00 00
					39 00 00 40 00 00 07 8B 00 00 10 04 08 04
					39 00 00 40 00 00 07 8C 00 00 10 04 10 04
					39 00 00 40 00 00 07 8D 00 00 10 04 20 04
					39 00 00 40 00 00 07 8E 00 00 10 04 3F BC
					39 00 00 40 00 00 07 8F 00 00 20 04 00 00
					39 00 00 40 00 00 07 90 00 00 20 04 08 04
					39 00 00 40 00 00 07 91 00 00 20 04 10 04
					39 00 00 40 00 00 07 92 00 00 20 04 20 04
					39 00 00 40 00 00 07 93 00 00 20 04 3F BC
					39 00 00 40 00 00 07 94 00 00 3F BC 00 00
					39 00 00 40 00 00 07 95 00 00 3F BC 08 04
					39 00 00 40 00 00 07 96 00 00 3F BC 10 04
					39 00 00 40 00 00 07 97 00 00 3F BC 20 04
					39 00 00 40 00 00 07 98 00 00 3F BC 3F BC
					39 00 00 40 00 00 07 99 04 CC 00 00 00 00
					39 00 00 40 00 00 07 9A 08 04 00 00 08 04
					39 00 00 40 00 00 07 9B 08 04 00 00 10 04
					39 00 00 40 00 00 07 9C 08 04 00 00 20 04
					39 00 00 40 00 00 07 9D 08 04 00 00 3F BC
					39 00 00 40 00 00 07 9E 08 04 08 04 00 00
					39 00 00 40 00 00 07 9F 04 CC 08 00 09 99
					39 00 00 40 00 00 07 A0 08 04 08 04 10 04
					39 00 00 40 00 00 07 A1 08 04 08 04 20 04
					39 00 00 40 00 00 07 A2 08 04 08 04 3F BC
					39 00 00 40 00 00 07 A3 08 04 10 04 00 00
					39 00 00 40 00 00 07 A4 08 04 10 04 08 04
					39 00 00 40 00 00 07 A5 08 04 10 04 10 04
					39 00 00 40 00 00 07 A6 08 04 10 04 20 04
					39 00 00 40 00 00 07 A7 08 04 10 04 3F BC
					39 00 00 40 00 00 07 A8 08 04 20 04 00 00
					39 00 00 40 00 00 07 A9 08 04 20 04 08 04
					39 00 00 40 00 00 07 AA 08 04 20 04 10 04
					39 00 00 40 00 00 07 AB 08 04 20 04 20 04
					39 00 00 40 00 00 07 AC 08 04 20 04 3F BC
					39 00 00 40 00 00 07 AD 08 04 3F BC 00 00
					39 00 00 40 00 00 07 AE 08 04 3F BC 08 04
					39 00 00 40 00 00 07 AF 08 04 3F BC 10 04
					39 00 00 40 00 00 07 B0 08 04 3F BC 20 04
					39 00 00 40 00 00 07 B1 08 04 3F BC 3F BC
					39 00 00 40 00 00 07 B2 09 99 00 00 00 00
					39 00 00 40 00 00 07 B3 10 04 00 00 08 04
					39 00 00 40 00 00 07 B4 10 04 00 00 10 04
					39 00 00 40 00 00 07 B5 10 04 00 00 20 04
					39 00 00 40 00 00 07 B6 10 04 00 00 3F BC
					39 00 00 40 00 00 07 B7 10 04 08 04 00 00
					39 00 00 40 00 00 07 B8 10 04 08 04 08 04
					39 00 00 40 00 00 07 B9 10 04 08 04 10 04
					39 00 00 40 00 00 07 BA 10 04 08 04 20 04
					39 00 00 40 00 00 07 BB 10 04 08 04 3F BC
					39 00 00 40 00 00 07 BC 10 04 10 04 00 00
					39 00 00 40 00 00 07 BD 10 04 10 04 08 04
					39 00 00 40 00 00 07 BE 09 99 10 04 13 33
					39 00 00 40 00 00 07 BF 10 04 10 04 20 04
					39 00 00 40 00 00 07 C0 10 04 10 04 3F BC
					39 00 00 40 00 00 07 C1 10 04 20 04 00 00
					39 00 00 40 00 00 07 C2 10 04 20 04 08 04
					39 00 00 40 00 00 07 C3 10 04 20 04 10 04
					39 00 00 40 00 00 07 C4 10 04 20 04 20 04
					39 00 00 40 00 00 07 C5 10 04 20 04 3F BC
					39 00 00 40 00 00 07 C6 10 04 3F BC 00 00
					39 00 00 40 00 00 07 C7 10 04 3F BC 08 04
					39 00 00 40 00 00 07 C8 10 04 3F BC 10 04
					39 00 00 40 00 00 07 C9 10 04 3F BC 20 04
					39 00 00 40 00 00 07 CA 10 04 3F BC 3F BC
					39 00 00 40 00 00 07 CB 20 04 00 00 00 00
					39 00 00 40 00 00 07 CC 20 04 00 00 08 04
					39 00 00 40 00 00 07 CD 20 04 00 00 10 04
					39 00 00 40 00 00 07 CE 20 04 00 00 20 04
					39 00 00 40 00 00 07 CF 20 04 00 00 3F BC
					39 00 00 40 00 00 07 D0 20 04 08 04 00 00
					39 00 00 40 00 00 07 D1 20 04 08 04 08 04
					39 00 00 40 00 00 07 D2 20 04 08 04 10 04
					39 00 00 40 00 00 07 D3 20 04 08 04 20 04
					39 00 00 40 00 00 07 D4 20 04 08 04 3F BC
					39 00 00 40 00 00 07 D5 20 04 10 04 00 00
					39 00 00 40 00 00 07 D6 20 04 10 04 08 04
					39 00 00 40 00 00 07 D7 20 04 10 04 10 04
					39 00 00 40 00 00 07 D8 20 04 10 04 20 04
					39 00 00 40 00 00 07 D9 20 04 10 04 3F BC
					39 00 00 40 00 00 07 DA 20 04 20 04 00 00
					39 00 00 40 00 00 07 DB 20 04 20 04 08 04
					39 00 00 40 00 00 07 DC 20 04 20 04 10 04
					39 00 00 40 00 00 07 DD 20 00 20 00 20 00
					39 00 00 40 00 00 07 DE 20 04 20 04 3F BC
					39 00 00 40 00 00 07 DF 20 04 3F BC 00 00
					39 00 00 40 00 00 07 E0 20 04 3F BC 08 04
					39 00 00 40 00 00 07 E1 20 04 3F BC 10 04
					39 00 00 40 00 00 07 E2 20 04 3F BC 20 04
					39 00 00 40 00 00 07 E3 20 04 3F BC 3F BC
					39 00 00 40 00 00 07 E4 3F BC 00 00 00 00
					39 00 00 40 00 00 07 E5 3F BC 00 00 08 04
					39 00 00 40 00 00 07 E6 3F BC 00 00 10 04
					39 00 00 40 00 00 07 E7 3F BC 00 00 20 04
					39 00 00 40 00 00 07 E8 3F BC 00 00 3F BC
					39 00 00 40 00 00 07 E9 3F BC 08 04 00 00
					39 00 00 40 00 00 07 EA 3F BC 08 04 08 04
					39 00 00 40 00 00 07 EB 3F BC 08 04 10 04
					39 00 00 40 00 00 07 EC 3F BC 08 04 20 04
					39 00 00 40 00 00 07 ED 3F BC 08 04 3F BC
					39 00 00 40 00 00 07 EE 3F BC 10 04 00 00
					39 00 00 40 00 00 07 EF 3F BC 10 04 08 04
					39 00 00 40 00 00 07 F0 3F BC 10 04 10 04
					39 00 00 40 00 00 07 F1 3F BC 10 04 20 04
					39 00 00 40 00 00 07 F2 3F BC 10 04 3F BC
					39 00 00 40 00 00 07 F3 3F BC 20 04 00 00
					39 00 00 40 00 00 07 F4 3F BC 20 04 08 04
					39 00 00 40 00 00 07 F5 3F BC 20 04 10 04
					39 00 00 40 00 00 07 F6 3F BC 20 04 20 04
					39 00 00 40 00 00 07 F7 3F BC 20 04 3F BC
					39 00 00 40 00 00 07 F8 3F BC 3F BC 00 00
					39 00 00 40 00 00 07 F9 3F BC 3F BC 08 04
					39 00 00 40 00 00 07 FA 3F BC 3F BC 10 04
					39 00 00 40 00 00 07 FB 3F BC 3F BC 20 04
					39 00 00 40 00 00 07 FC 3F C0 3F C0 3F C0
					/* 125 point mapping value for DBV2 */
					39 00 00 40 00 00 04 FF 5A A5 71
					39 00 00 40 00 00 07 80 00 00 00 00 00 00
					39 00 00 40 00 00 07 81 00 00 00 00 09 99
					39 00 00 40 00 00 07 82 00 00 00 00 13 33
					39 00 00 40 00 00 07 83 00 00 00 00 20 04
					39 00 00 40 00 00 07 84 00 00 00 00 3F BC
					39 00 00 40 00 00 07 85 00 00 08 04 00 00
					39 00 00 40 00 00 07 86 00 00 08 04 08 04
					39 00 00 40 00 00 07 87 00 00 08 04 10 04
					39 00 00 40 00 00 07 88 00 00 08 04 20 04
					39 00 00 40 00 00 07 89 00 00 08 04 3F BC
					39 00 00 40 00 00 07 8A 00 00 10 04 00 00
					39 00 00 40 00 00 07 8B 00 00 10 04 08 04
					39 00 00 40 00 00 07 8C 00 00 10 04 10 04
					39 00 00 40 00 00 07 8D 00 00 10 04 20 04
					39 00 00 40 00 00 07 8E 00 00 10 04 3F BC
					39 00 00 40 00 00 07 8F 00 00 20 04 00 00
					39 00 00 40 00 00 07 90 00 00 20 04 08 04
					39 00 00 40 00 00 07 91 00 00 20 04 10 04
					39 00 00 40 00 00 07 92 00 00 20 04 20 04
					39 00 00 40 00 00 07 93 00 00 20 04 3F BC
					39 00 00 40 00 00 07 94 00 00 3F BC 00 00
					39 00 00 40 00 00 07 95 00 00 3F BC 08 04
					39 00 00 40 00 00 07 96 00 00 3F BC 10 04
					39 00 00 40 00 00 07 97 00 00 3F BC 20 04
					39 00 00 40 00 00 07 98 00 00 3F BC 3F BC
					39 00 00 40 00 00 07 99 04 CC 00 00 00 00
					39 00 00 40 00 00 07 9A 08 04 00 00 08 04
					39 00 00 40 00 00 07 9B 08 04 00 00 10 04
					39 00 00 40 00 00 07 9C 08 04 00 00 20 04
					39 00 00 40 00 00 07 9D 08 04 00 00 3F BC
					39 00 00 40 00 00 07 9E 08 04 08 04 00 00
					39 00 00 40 00 00 07 9F 04 CC 08 00 09 99
					39 00 00 40 00 00 07 A0 08 04 08 04 10 04
					39 00 00 40 00 00 07 A1 08 04 08 04 20 04
					39 00 00 40 00 00 07 A2 08 04 08 04 3F BC
					39 00 00 40 00 00 07 A3 08 04 10 04 00 00
					39 00 00 40 00 00 07 A4 08 04 10 04 08 04
					39 00 00 40 00 00 07 A5 08 04 10 04 10 04
					39 00 00 40 00 00 07 A6 08 04 10 04 20 04
					39 00 00 40 00 00 07 A7 08 04 10 04 3F BC
					39 00 00 40 00 00 07 A8 08 04 20 04 00 00
					39 00 00 40 00 00 07 A9 08 04 20 04 08 04
					39 00 00 40 00 00 07 AA 08 04 20 04 10 04
					39 00 00 40 00 00 07 AB 08 04 20 04 20 04
					39 00 00 40 00 00 07 AC 08 04 20 04 3F BC
					39 00 00 40 00 00 07 AD 08 04 3F BC 00 00
					39 00 00 40 00 00 07 AE 08 04 3F BC 08 04
					39 00 00 40 00 00 07 AF 08 04 3F BC 10 04
					39 00 00 40 00 00 07 B0 08 04 3F BC 20 04
					39 00 00 40 00 00 07 B1 08 04 3F BC 3F BC
					39 00 00 40 00 00 07 B2 09 99 00 00 00 00
					39 00 00 40 00 00 07 B3 10 04 00 00 08 04
					39 00 00 40 00 00 07 B4 10 04 00 00 10 04
					39 00 00 40 00 00 07 B5 10 04 00 00 20 04
					39 00 00 40 00 00 07 B6 10 04 00 00 3F BC
					39 00 00 40 00 00 07 B7 10 04 08 04 00 00
					39 00 00 40 00 00 07 B8 10 04 08 04 08 04
					39 00 00 40 00 00 07 B9 10 04 08 04 10 04
					39 00 00 40 00 00 07 BA 10 04 08 04 20 04
					39 00 00 40 00 00 07 BB 10 04 08 04 3F BC
					39 00 00 40 00 00 07 BC 10 04 10 04 00 00
					39 00 00 40 00 00 07 BD 10 04 10 04 08 04
					39 00 00 40 00 00 07 BE 09 99 10 04 13 33
					39 00 00 40 00 00 07 BF 10 04 10 04 20 04
					39 00 00 40 00 00 07 C0 10 04 10 04 3F BC
					39 00 00 40 00 00 07 C1 10 04 20 04 00 00
					39 00 00 40 00 00 07 C2 10 04 20 04 08 04
					39 00 00 40 00 00 07 C3 10 04 20 04 10 04
					39 00 00 40 00 00 07 C4 10 04 20 04 20 04
					39 00 00 40 00 00 07 C5 10 04 20 04 3F BC
					39 00 00 40 00 00 07 C6 10 04 3F BC 00 00
					39 00 00 40 00 00 07 C7 10 04 3F BC 08 04
					39 00 00 40 00 00 07 C8 10 04 3F BC 10 04
					39 00 00 40 00 00 07 C9 10 04 3F BC 20 04
					39 00 00 40 00 00 07 CA 10 04 3F BC 3F BC
					39 00 00 40 00 00 07 CB 20 04 00 00 00 00
					39 00 00 40 00 00 07 CC 20 04 00 00 08 04
					39 00 00 40 00 00 07 CD 20 04 00 00 10 04
					39 00 00 40 00 00 07 CE 20 04 00 00 20 04
					39 00 00 40 00 00 07 CF 20 04 00 00 3F BC
					39 00 00 40 00 00 07 D0 20 04 08 04 00 00
					39 00 00 40 00 00 07 D1 20 04 08 04 08 04
					39 00 00 40 00 00 07 D2 20 04 08 04 10 04
					39 00 00 40 00 00 07 D3 20 04 08 04 20 04
					39 00 00 40 00 00 07 D4 20 04 08 04 3F BC
					39 00 00 40 00 00 07 D5 20 04 10 04 00 00
					39 00 00 40 00 00 07 D6 20 04 10 04 08 04
					39 00 00 40 00 00 07 D7 20 04 10 04 10 04
					39 00 00 40 00 00 07 D8 20 04 10 04 20 04
					39 00 00 40 00 00 07 D9 20 04 10 04 3F BC
					39 00 00 40 00 00 07 DA 20 04 20 04 00 00
					39 00 00 40 00 00 07 DB 20 04 20 04 08 04
					39 00 00 40 00 00 07 DC 20 04 20 04 10 04
					39 00 00 40 00 00 07 DD 20 00 20 00 20 00
					39 00 00 40 00 00 07 DE 20 04 20 04 3F BC
					39 00 00 40 00 00 07 DF 20 04 3F BC 00 00
					39 00 00 40 00 00 07 E0 20 04 3F BC 08 04
					39 00 00 40 00 00 07 E1 20 04 3F BC 10 04
					39 00 00 40 00 00 07 E2 20 04 3F BC 20 04
					39 00 00 40 00 00 07 E3 20 04 3F BC 3F BC
					39 00 00 40 00 00 07 E4 3F BC 00 00 00 00
					39 00 00 40 00 00 07 E5 3F BC 00 00 08 04
					39 00 00 40 00 00 07 E6 3F BC 00 00 10 04
					39 00 00 40 00 00 07 E7 3F BC 00 00 20 04
					39 00 00 40 00 00 07 E8 3F BC 00 00 3F BC
					39 00 00 00 00 00 07 E9 3F BC 08 04 00 00
					39 00 00 40 00 00 07 EA 3F BC 08 04 08 04
					39 00 00 40 00 00 07 EB 3F BC 08 04 10 04
					39 00 00 40 00 00 07 EC 3F BC 08 04 20 04
					39 00 00 40 00 00 07 ED 3F BC 08 04 3F BC
					39 00 00 40 00 00 07 EE 3F BC 10 04 00 00
					39 00 00 40 00 00 07 EF 3F BC 10 04 08 04
					39 00 00 40 00 00 07 F0 3F BC 10 04 10 04
					39 00 00 40 00 00 07 F1 3F BC 10 04 20 04
					39 00 00 40 00 00 07 F2 3F BC 10 04 3F BC
					39 00 00 40 00 00 07 F3 3F BC 20 04 00 00
					39 00 00 40 00 00 07 F4 3F BC 20 04 08 04
					39 00 00 40 00 00 07 F5 3F BC 20 04 10 04
					39 00 00 40 00 00 07 F6 3F BC 20 04 20 04
					39 00 00 40 00 00 07 F7 3F BC 20 04 3F BC
					39 00 00 40 00 00 07 F8 3F BC 3F BC 00 00
					39 00 00 40 00 00 07 F9 3F BC 3F BC 08 04
					39 00 00 40 00 00 07 FA 3F BC 3F BC 10 04
					39 00 00 40 00 00 07 FB 3F BC 3F BC 20 04
					39 00 00 00 00 00 07 FC 3F C0 3F C0 3F C0

					05 00 00 00 78 00 01 11 // Sleep OUT
					/* TE raise */
					39 00 00 00 00 00 04 FF 5A A5 22
					39 00 00 00 00 00 08 D8 00 DB 11 10 32 14 14
					39 00 00 00 00 00 08 D9 00 DB 11 10 32 14 14
					39 00 00 00 00 00 08 DA 00 DB 11 10 32 14 14
					39 00 00 00 00 00 08 DB 00 DB 11 10 32 14 14
					39 00 00 00 00 00 0A DC 84 94 BB 00 20 C4 A1 CC 10
					39 00 00 00 00 00 02 DD 01
					39 00 00 00 00 00 02 DE F1
					39 00 00 00 00 00 02 DF 80
					39 00 00 00 00 00 08 E0 02 00 5F 21 00 28 00
					39 00 00 00 00 00 04 FF 5A A5 00
					39 00 00 00 00 00 01 29 // Display ON
				];
				oplus,dsi-aod-off-command = [
					39 00 00 40 00 00 04 FF 5A A5 02
					39 00 00 40 00 00 03 AB AF 82 //TE Shift ON
					39 00 00 40 00 00 03 88 C0 00
					39 00 00 40 00 00 04 FF 5A A5 00
					39 00 00 40 00 00 02 38 00
					39 00 00 00 00 00 05 51 00 00 00 00
				];
				oplus,dsi-ultra-low-power-aod-on-command = [
					39 00 00 40 00 00 04 FF 5A A5 2D
					39 00 00 40 00 00 03 8A 1D 00
					39 00 00 00 00 00 04 FF 5A A5 00
				];
				oplus,dsi-ultra-low-power-aod-off-command = [
					39 00 00 40 00 00 04 FF 5A A5 2D
					39 00 00 40 00 00 03 8A 00 00
					39 00 00 00 00 00 04 FF 5A A5 00
				];
				oplus,dsi-hbm-on-command = [
					39 00 00 00 00 00 03 51 0E E0
				];
				oplus,dsi-hbm-off-command = [
					39 00 00 00 00 00 03 51 0D BB
				];
				oplus,dsi-adfr-min-fps-120hz-command = [
					39 00 00 40 00 00 04 FF 5A A5 2D
					39 00 00 40 00 00 03 83 00 00
					39 00 00 40 00 00 03 84 00 00
					39 00 00 00 00 00 04 FF 5A A5 00
				];
				oplus,dsi-adfr-min-fps-60hz-command = [
					39 00 00 40 00 00 04 FF 5A A5 2D
					39 00 00 40 00 00 03 83 01 00
					39 00 00 40 00 00 03 84 01 00
					39 00 00 00 00 00 04 FF 5A A5 00
				];
				oplus,dsi-adfr-min-fps-30hz-command = [
					39 00 00 40 00 00 04 FF 5A A5 2D
					39 00 00 40 00 00 03 83 03 00
					39 00 00 40 00 00 03 84 03 00
					39 00 00 00 00 00 04 FF 5A A5 00
				];
				oplus,dsi-adfr-min-fps-20hz-command = [
					39 00 00 40 00 00 04 FF 5A A5 2D
					39 00 00 40 00 00 03 83 05 00
					39 00 00 40 00 00 03 84 05 00
					39 00 00 00 00 00 04 FF 5A A5 00
				];
				oplus,dsi-adfr-min-fps-10hz-command = [
					39 00 00 40 00 00 04 FF 5A A5 2D
					39 00 00 40 00 00 03 83 0B 00
					39 00 00 40 00 00 03 84 0B 00
					39 00 00 00 00 00 04 FF 5A A5 00
				];
				oplus,dsi-adfr-min-fps-5hz-command = [
					39 00 00 40 00 00 04 FF 5A A5 2D
					39 00 00 40 00 00 03 83 17 00
					39 00 00 40 00 00 03 84 17 00
					39 00 00 00 00 00 04 FF 5A A5 00
				];
				oplus,dsi-adfr-min-fps-1hz-command = [
					39 00 00 40 00 00 04 FF 5A A5 2D
					39 00 00 40 00 00 03 83 77 00
					39 00 00 40 00 00 03 84 77 00
					39 00 00 00 00 00 04 FF 5A A5 00
				];
				oplus,dsi-pwm-switch-1to3pul-command = [
					39 00 00 40 00 00 04 FF 5A A5 53
					39 00 00 40 00 00 03 85 CC E1 // Normal Demura
					39 00 00 40 00 00 04 FF 5A A5 00
					39 00 00 00 00 00 02 60 00
				];
				oplus,dsi-pwm-switch-3to1pul-command = [
					39 00 00 40 00 00 04 FF 5A A5 53
					39 00 00 40 00 00 03 85 CC E3 // DC Demura
					39 00 00 40 00 00 04 FF 5A A5 00
					39 00 00 00 00 00 02 60 01
				];

				oplus,dsi-timing-switch-command-state = "dsi_hs_mode";
				oplus,dsi-timing-switch-1pulse-command-state = "dsi_hs_mode";
				oplus,dsi-on-command-state = "dsi_lp_mode";
				oplus,dsi-aod-off-command-state = "dsi_ls_mode";
				oplus,dsi-ultra-low-power-aod-off-command-state = "dsi_ls_mode";
				oplus,dsi-ultra-low-power-aod-on-command-state = "dsi_ls_mode";
				oplus,dsi-hbm-on-command-state = "dsi_hs_mode";
				oplus,dsi-hbm-off-command-state = "dsi_hs_mode";
				oplus,dsi-auto-off-minfps-command-state = "dsi_hs_mode";
				oplus,dsi-pwm-switch-1to3pul-command-state = "dsi_hs_mode";
				oplus,dsi-pwm-switch-3to1pul-command-state = "dsi_hs_mode";
				oplus,dsi-adfr-min-fps-120hz-command-state = "dsi_hs_mode";
				oplus,dsi-adfr-min-fps-60hz-command-state = "dsi_hs_mode";
				oplus,dsi-adfr-min-fps-30hz-command-state = "dsi_hs_mode";
				oplus,dsi-adfr-min-fps-20hz-command-state = "dsi_hs_mode";
				oplus,dsi-adfr-min-fps-10hz-command-state = "dsi_hs_mode";
				oplus,dsi-adfr-min-fps-5hz-command-state = "dsi_hs_mode";
				oplus,dsi-adfr-min-fps-1hz-command-state = "dsi_hs_mode";
				oplus,dsc-params-entries = <&dsc_params>;
				oplus,spr-params-entries = <&spr_params>;
				oplus,phy-timcon {
					hs-trail = <14>;
					clk-trail = <15>;
				};
				oplus,dyn-fps {
					switch_en = <1>;
					vact_timing_fps = <120>;
					apollo_limit_superior_us = <4900>;
					apollo_limit_inferior_us = <6750>;
					apollo_transfer_time_us = <6200>;
				};
				oplus,display-mode {
					display-mode@0 {
						hdisplay = <1264>;
						vdisplay = <2780>;
						fhd-hfp = <9>;
						fhd-hsa = <2>;
						fhd-hbp = <21>;
						fhd-vfp = <52>;
						fhd-vsa = <14>;
						fhd-vbp = <22>;
						hskew = <0>;
					};
					display-mode@1 {
						hdisplay = <1080>;
						vdisplay = <2376>;
						fhd-hfp = <9>;
						fhd-hsa = <2>;
						fhd-hbp = <21>;
						fhd-vfp = <66>;
						fhd-vsa = <24>;
						fhd-vbp = <36>;
						hskew = <0>;
					};
				};
			};
			timing@oa_fhd_120 {
				cell-index = <3>;
				oplus,dsi-panel-framerate = <120>;
				oplus,adfr-timing-type = <2>;
				oplus,dsi-panel-pllclk = <556>;
				oplus,cmd-null-pkt-en = <0>;
				oplus,cmd-null-pkt-len = <0>;
				oplus,merge-trig-offset = <333>;
				oplus,vidle-te-duration = <7900>;
				/* OPLUS_FEATURE_DISPLAY_ONSCREENFINGERPRINT */
				oplus,ofp_need_keep_apart_backlight;
				oplus,ofp-hbm-on-delay = <0>;
				oplus,ofp-pre-hbm-off-delay = <6>;
				oplus,ofp-hbm-off-delay = <0>;
				oplus,ofp-need-to-sync-data-in-aod-unlocking;
				oplus,ofp-aod-off-insert-black = <2>;
				oplus,ofp-aod-off-black-frame-total-time = <42>;
				#include "panel-ac180-p-3-a0020-dsi-cmd-common-T0.dtsi"
				oplus,dsi-timing-switch-command = [
					39 00 00 40 00 00 04 FF 5A A5 00
					39 00 00 40 00 00 02 60 00 // 0x00: 120Hz 02: 90Hz
					39 00 00 40 00 00 04 FF 5A A5 53
					39 00 00 40 00 00 03 85 CC E1 // Normal Demura
					39 00 00 40 00 00 04 FF 5A A5 2D
					39 00 00 40 00 00 03 83 00 00
					39 00 00 40 00 00 02 F2 00
					39 00 00 00 00 00 04 FF 5A A5 00
				];
				oplus,dsi-timing-switch-1pulse-command = [
					39 00 00 40 00 00 04 FF 5A A5 00
					39 00 00 40 00 00 02 60 01 // 0x01: 120Hz 03: 90Hz
					39 00 00 40 00 00 04 FF 5A A5 53
					39 00 00 40 00 00 03 85 CC E3 // DC Demura
					39 00 00 40 00 00 04 FF 5A A5 2D
					39 00 00 40 00 00 03 84 00 00
					39 00 00 40 00 00 02 F2 00
					39 00 00 00 00 00 04 FF 5A A5 00
				];
				oplus,dsi-on-command = [
					39 00 00 00 00 00 04 FF 5A A5 08
					39 00 00 00 00 00 02 C8 62 // Sleep out don't reload
					39 00 00 00 00 00 04 FF 5A A5 10 //lhbm mode control begin
					39 00 00 00 00 00 27 8F C8 7C 00 42 00 80 10 00 5A 00 59 58 00 40 1F 00 0D 08 00 05 03 00 02 00 00 00 00 00 00 00 00 00 00 00 00 00 00 00
					39 00 00 00 00 00 04 FF 5A A5 24
					39 00 00 00 00 00 09 A5 0F FF 0F FE 0D BB 0B 1A
					39 00 00 00 00 00 09 A6 07 52 04 8B 04 8A 04 76
					39 00 00 00 00 00 09 A7 03 E6 02 CB 01 E1 01 7D
					39 00 00 00 00 00 09 A8 01 19 00 B5 00 01 00 00
					39 00 00 00 00 00 09 A9 00 00 00 00 00 00 00 00
					39 00 00 00 00 00 09 AA 00 00 00 00 00 00 00 00
					39 00 00 00 00 00 03 AB 00 00
					39 00 00 00 00 00 04 FF 5A A5 29
					39 00 00 00 00 00 09 93 0F FF 0F FE 0D BB 0B 1A
					39 00 00 00 00 00 09 94 07 52 04 8B 04 8A 04 76
					39 00 00 00 00 00 09 95 03 E6 02 CB 01 E1 01 7D
					39 00 00 00 00 00 09 96 01 19 00 B5 00 01 00 00
					39 00 00 00 00 00 09 97 00 00 00 00 00 00 00 00
					39 00 00 00 00 00 09 98 00 00 00 00 00 00 00 00
					39 00 00 00 00 00 09 99 00 00 00 00 00 00 00 00
					39 00 00 00 00 00 05 9A 00 00 00 00
					39 00 00 00 00 00 04 FF 5A A5 00
					39 00 00 00 00 00 02 4F 31
					39 00 00 00 00 00 04 FF 5A A5 1E
					39 00 00 00 00 00 02 80 89
					39 00 00 00 00 00 02 85 10
					39 00 00 00 00 00 02 9A 3F
					39 00 00 00 00 00 02 9B 01
					39 00 00 00 00 00 18 94 00 00 23 00 68 CF 12 58 03 23 D0 BF 46 D0 03 78 58 CF AC 68 23 0E 00
					39 00 00 00 00 00 19 95 00 00 12 00 46 9C 11 14 AE 23 6A 48 45 48 6A 68 AE 14 9B 9C 46 DF 12 00
					39 00 00 00 00 00 0D 96 FD F3 E6 CD B3 9A 80 66 4D 33 1A 00
					39 00 00 00 00 00 13 97 00 29 CC 13 98 30 46 C8 60 79 F8 90 BC 28 C0 EF 58 F0
					39 00 00 00 00 00 04 FF 5A A5 1F
					39 00 00 00 00 00 02 C0 08
					39 00 00 00 00 00 04 FF 5A A5 00
					39 00 00 00 00 00 02 6E 00
					39 00 00 00 00 00 04 FF 5A A5 1E
					39 00 00 00 00 00 02 C0 10
					39 00 00 00 00 00 04 C1 70 9C C1
					39 00 00 00 00 00 09 C2 FF FF FF 61 36 63 46 00
					39 00 00 00 00 00 27 C5 44 00 00 44 00 00 44 00 00 33 FE F7 32 72 77 11 A7 6C 11 3B 08 00 C1 00 00 00 00 00 00 00 00 00 00 00 00 00 00 00
					39 00 00 00 00 00 09 C6 44 00 00 21 00 00 00 80
					39 00 00 00 00 00 27 C7 44 00 00 33 8B 17 21 19 58 11 55 50 10 22 D8 00 99 59 00 00 00 00 00 00 00 00 00 00 00 00 00 00 00 00 00 00 00 00
					39 00 00 00 00 00 09 C8 44 00 00 32 00 00 01 00
					39 00 00 00 00 00 02 C9 30
					39 00 00 00 00 00 04 FF 5A A5 1F
					39 00 00 00 00 00 02 C0 08
					39 00 00 00 00 00 1F C2 FF FF FF AB EA FF FF FF FC FC FF FC FC FC FF FF FF FF FF FF FF FF FF FF FF FF FF FF FF FF
					39 00 00 00 00 00 04 FF 5A A5 24
					39 00 00 00 00 00 02 80 04
					39 00 00 00 00 00 02 81 8B
					39 00 00 00 00 00 02 82 0F
					39 00 00 00 00 00 02 83 FE
					39 00 00 00 00 00 02 84 00
					39 00 00 00 00 00 04 FF 5A A5 00
					39 00 00 00 00 00 02 95 FF
					39 00 00 00 00 00 02 96 09
					39 00 00 00 00 00 02 97 D9
					39 00 00 00 00 00 02 98 02
					39 00 00 00 00 00 02 99 78 //lhbm mode control end
					39 00 00 00 00 00 04 FF 5A A5 07
					39 00 00 00 00 00 02 8A 01 // PPS Enable
					39 00 00 00 00 00 03 8B 11 E0 // PPS Table
					39 00 00 00 00 00 64 80 00 00 00 00 00 12 00 00 A0 21 00 0A DC 04 F0 00 0A 02 78 02 78 01 55 01 D0 00 0A 00 89 00 35 00 0C 0A AB 31 07 08 00 0C 10 07 10 20 00 06 0F 0F 33 0E 1C 2A 38 46 54 62 69 70 77 79 7B 7D 7E 00 82 11 40 19 C0 22 3E 32 7C 3A BA 3A F8 3B 38 3B 38 3B 76 4B 76 4B 74 4B 74 5B B4 73 F4 01 00 00 00 00 00
					39 00 00 00 00 00 64 81 00 00 00 00 00 12 00 00 AB 30 80 0A DC 04 F0 00 14 02 78 02 78 02 00 02 57 00 20 01 F8 00 08 00 0D 05 7A 04 4F 18 00 10 E0 07 10 20 00 06 0F 0F 33 0E 1C 2A 38 46 54 62 69 70 77 79 7B 7D 7E 02 02 22 00 2A 40 2A BE 3A FC 3A FA 3A F8 3B 38 3B 78 3B B6 4B B6 4B F4 4B F4 6C 34 84 74 00 00 00 00 00 00
					39 00 00 00 00 00 02 91 00
					39 00 00 00 00 00 04 FF 5A A5 07
					39 00 00 00 00 00 03 8B 11 A0
					39 00 00 00 00 00 04 FF 5A A5 14
					39 00 00 00 00 00 02 82 01 // SPR IN AP ON
					39 00 00 00 00 00 04 FF 5A A5 21
					39 00 00 00 00 00 02 A4 18 // Flash reload enable
					39 00 00 00 00 00 04 FF 5A A5 13
					39 00 00 00 00 00 03 FB 18 27 // Hole related
					39 00 00 00 00 00 04 FF 5A A5 2D
					39 00 00 00 00 00 02 F2 00 // 0x00:120Hz 01:60Hz
					39 00 00 00 00 00 03 83 00 00 // 120Hz skip frame
					39 00 00 00 00 00 03 84 00 00 // 120Hz skip frame (1pulse)
					39 00 00 00 00 00 03 85 00 00 // 90Hz skip frame
					39 00 00 00 00 00 03 86 00 00 // 90Hz skip frame (1pulse)
					39 00 00 00 00 00 04 FF 5A A5 00
					39 00 00 00 00 00 02 5A 01 // ADFR
					39 00 00 00 00 00 02 5B 80 // ADFR
					39 00 00 00 00 00 04 FF 5A A5 02
					39 00 00 00 00 00 02 C0 03
					39 00 00 00 00 00 04 FF 5A A5 2D
					39 00 00 00 00 00 04 EC 01 AF 00
					39 00 00 00 00 00 03 93 A0 00
					39 00 00 00 00 00 03 94 C4 00
					39 00 00 00 00 00 03 95 00 00
					39 00 00 00 00 00 03 96 00 00
					39 00 00 00 00 00 03 ED D5 00
					39 00 00 00 00 00 04 EE 00 00 00
					/* decreasing step */
					39 00 00 00 00 00 02 97 03
					39 00 00 00 00 00 02 B1 03
					39 00 00 00 00 00 03 98 03 00
					39 00 00 00 00 00 03 99 05 00
					39 00 00 00 00 00 03 9A 0B 00
					39 00 00 00 00 00 03 9B 17 00
					39 00 00 00 00 00 03 A0 00 00
					39 00 00 00 00 00 03 A1 01 02
					39 00 00 00 00 00 02 B2 02
					39 00 00 00 00 00 02 B3 04
					39 00 00 00 00 00 02 B4 08
					39 00 00 00 00 00 02 B5 11
					39 00 00 00 00 00 03 BA 00 00
					39 00 00 00 00 00 03 BB 01 02
					39 00 00 00 00 00 04 FF 5A A5 02
					39 00 00 00 00 00 09 B0 00 80 00 10 00 00 00 00
					39 00 00 00 00 00 03 AB AF 82 // TE Left Shift 2ms
					39 00 00 00 00 00 04 FF 5A A5 31
					39 00 00 00 00 00 02 A0 A1 // CTB ON
					39 00 00 00 00 00 04 FF 5A A5 49
					39 00 00 00 00 00 02 E0 01 // ODC ON
					39 00 00 00 00 00 04 FF 5A A5 53
					39 00 00 00 00 00 03 80 0F 40 // Demura ON
					39 00 00 00 00 00 03 85 CC E1 // Loading demura data
					39 00 00 00 00 00 04 FF 5A A5 17
					39 00 00 00 00 00 02 A0 00 // RCN OFF
					/* AVEE PUMP 4H */
					39 00 00 00 00 00 04 FF 5A A5 02
					39 00 00 00 00 00 0A E5 09 0B 0B 0D 55 0D 32 32 32
					39 00 00 00 00 00 03 E7 33 25
					39 00 00 00 00 00 03 E8 33 25
					39 00 00 00 00 00 03 E9 33 25
					39 00 00 00 00 00 03 EA 33 25
					39 00 00 00 00 00 04 FF 5A A5 12
					39 00 00 00 00 00 02 81 33 // SRC keep vsp 2 frame
					39 00 00 00 00 00 04 FF 5A A5 00
					39 00 00 00 00 00 02 5E 01 // Skip frame Enable
					39 00 00 00 00 00 02 60 00 // Normal mode: 120Hz (3pulse)
					39 00 00 00 00 00 02 61 07 // AOD in mode
					39 00 00 00 00 00 02 35 00 // TE On
					39 00 00 00 00 00 02 53 20 // BC On Dimming OFF

					/* 3D LUT register */
					/* 3D LUT switch */
					39 00 00 40 00 00 04 FF 5A A5 00
					15 00 00 40 00 00 02 4D 00
					/* Gray binding points and DBV */
					39 00 00 40 00 00 04 FF 5A A5 4F
					15 00 00 40 00 00 02 91 00
					15 00 00 40 00 00 02 92 00
					15 00 00 40 00 00 02 93 08
					15 00 00 40 00 00 02 94 00
					15 00 00 40 00 00 02 95 10
					15 00 00 40 00 00 02 96 00
					15 00 00 40 00 00 02 97 20
					15 00 00 40 00 00 02 98 00
					15 00 00 40 00 00 02 99 20
					15 00 00 40 00 00 02 9A 00
					15 00 00 40 00 00 02 A0 00
					15 00 00 40 00 00 02 A1 01
					15 00 00 40 00 00 02 A2 0A
					15 00 00 40 00 00 02 A3 81
					15 00 00 40 00 00 02 A4 0F
					15 00 00 40 00 00 02 A5 FF
					/* Matrix_off && LUT3D_off && Gray2bypass */
					15 00 00 40 00 00 02 AC 0C
					/* Gamma && Degamma */
					39 00 00 40 00 00 04 FF 5A A5 13
					15 00 00 40 00 00 02 CA 70
					/* 125 point mapping value for DBV1 */
					39 00 00 40 00 00 04 FF 5A A5 70
					39 00 00 40 00 00 07 80 00 00 00 00 00 00
					39 00 00 40 00 00 07 81 00 00 00 00 09 99
					39 00 00 40 00 00 07 82 00 00 00 00 13 33
					39 00 00 40 00 00 07 83 00 00 00 00 20 04
					39 00 00 40 00 00 07 84 00 00 00 00 3F BC
					39 00 00 40 00 00 07 85 00 00 08 04 00 00
					39 00 00 40 00 00 07 86 00 00 08 04 08 04
					39 00 00 40 00 00 07 87 00 00 08 04 10 04
					39 00 00 40 00 00 07 88 00 00 08 04 20 04
					39 00 00 40 00 00 07 89 00 00 08 04 3F BC
					39 00 00 40 00 00 07 8A 00 00 10 04 00 00
					39 00 00 40 00 00 07 8B 00 00 10 04 08 04
					39 00 00 40 00 00 07 8C 00 00 10 04 10 04
					39 00 00 40 00 00 07 8D 00 00 10 04 20 04
					39 00 00 40 00 00 07 8E 00 00 10 04 3F BC
					39 00 00 40 00 00 07 8F 00 00 20 04 00 00
					39 00 00 40 00 00 07 90 00 00 20 04 08 04
					39 00 00 40 00 00 07 91 00 00 20 04 10 04
					39 00 00 40 00 00 07 92 00 00 20 04 20 04
					39 00 00 40 00 00 07 93 00 00 20 04 3F BC
					39 00 00 40 00 00 07 94 00 00 3F BC 00 00
					39 00 00 40 00 00 07 95 00 00 3F BC 08 04
					39 00 00 40 00 00 07 96 00 00 3F BC 10 04
					39 00 00 40 00 00 07 97 00 00 3F BC 20 04
					39 00 00 40 00 00 07 98 00 00 3F BC 3F BC
					39 00 00 40 00 00 07 99 04 CC 00 00 00 00
					39 00 00 40 00 00 07 9A 08 04 00 00 08 04
					39 00 00 40 00 00 07 9B 08 04 00 00 10 04
					39 00 00 40 00 00 07 9C 08 04 00 00 20 04
					39 00 00 40 00 00 07 9D 08 04 00 00 3F BC
					39 00 00 40 00 00 07 9E 08 04 08 04 00 00
					39 00 00 40 00 00 07 9F 04 CC 08 00 09 99
					39 00 00 40 00 00 07 A0 08 04 08 04 10 04
					39 00 00 40 00 00 07 A1 08 04 08 04 20 04
					39 00 00 40 00 00 07 A2 08 04 08 04 3F BC
					39 00 00 40 00 00 07 A3 08 04 10 04 00 00
					39 00 00 40 00 00 07 A4 08 04 10 04 08 04
					39 00 00 40 00 00 07 A5 08 04 10 04 10 04
					39 00 00 40 00 00 07 A6 08 04 10 04 20 04
					39 00 00 40 00 00 07 A7 08 04 10 04 3F BC
					39 00 00 40 00 00 07 A8 08 04 20 04 00 00
					39 00 00 40 00 00 07 A9 08 04 20 04 08 04
					39 00 00 40 00 00 07 AA 08 04 20 04 10 04
					39 00 00 40 00 00 07 AB 08 04 20 04 20 04
					39 00 00 40 00 00 07 AC 08 04 20 04 3F BC
					39 00 00 40 00 00 07 AD 08 04 3F BC 00 00
					39 00 00 40 00 00 07 AE 08 04 3F BC 08 04
					39 00 00 40 00 00 07 AF 08 04 3F BC 10 04
					39 00 00 40 00 00 07 B0 08 04 3F BC 20 04
					39 00 00 40 00 00 07 B1 08 04 3F BC 3F BC
					39 00 00 40 00 00 07 B2 09 99 00 00 00 00
					39 00 00 40 00 00 07 B3 10 04 00 00 08 04
					39 00 00 40 00 00 07 B4 10 04 00 00 10 04
					39 00 00 40 00 00 07 B5 10 04 00 00 20 04
					39 00 00 40 00 00 07 B6 10 04 00 00 3F BC
					39 00 00 40 00 00 07 B7 10 04 08 04 00 00
					39 00 00 40 00 00 07 B8 10 04 08 04 08 04
					39 00 00 40 00 00 07 B9 10 04 08 04 10 04
					39 00 00 40 00 00 07 BA 10 04 08 04 20 04
					39 00 00 40 00 00 07 BB 10 04 08 04 3F BC
					39 00 00 40 00 00 07 BC 10 04 10 04 00 00
					39 00 00 40 00 00 07 BD 10 04 10 04 08 04
					39 00 00 40 00 00 07 BE 09 99 10 04 13 33
					39 00 00 40 00 00 07 BF 10 04 10 04 20 04
					39 00 00 40 00 00 07 C0 10 04 10 04 3F BC
					39 00 00 40 00 00 07 C1 10 04 20 04 00 00
					39 00 00 40 00 00 07 C2 10 04 20 04 08 04
					39 00 00 40 00 00 07 C3 10 04 20 04 10 04
					39 00 00 40 00 00 07 C4 10 04 20 04 20 04
					39 00 00 40 00 00 07 C5 10 04 20 04 3F BC
					39 00 00 40 00 00 07 C6 10 04 3F BC 00 00
					39 00 00 40 00 00 07 C7 10 04 3F BC 08 04
					39 00 00 40 00 00 07 C8 10 04 3F BC 10 04
					39 00 00 40 00 00 07 C9 10 04 3F BC 20 04
					39 00 00 40 00 00 07 CA 10 04 3F BC 3F BC
					39 00 00 40 00 00 07 CB 20 04 00 00 00 00
					39 00 00 40 00 00 07 CC 20 04 00 00 08 04
					39 00 00 40 00 00 07 CD 20 04 00 00 10 04
					39 00 00 40 00 00 07 CE 20 04 00 00 20 04
					39 00 00 40 00 00 07 CF 20 04 00 00 3F BC
					39 00 00 40 00 00 07 D0 20 04 08 04 00 00
					39 00 00 40 00 00 07 D1 20 04 08 04 08 04
					39 00 00 40 00 00 07 D2 20 04 08 04 10 04
					39 00 00 40 00 00 07 D3 20 04 08 04 20 04
					39 00 00 40 00 00 07 D4 20 04 08 04 3F BC
					39 00 00 40 00 00 07 D5 20 04 10 04 00 00
					39 00 00 40 00 00 07 D6 20 04 10 04 08 04
					39 00 00 40 00 00 07 D7 20 04 10 04 10 04
					39 00 00 40 00 00 07 D8 20 04 10 04 20 04
					39 00 00 40 00 00 07 D9 20 04 10 04 3F BC
					39 00 00 40 00 00 07 DA 20 04 20 04 00 00
					39 00 00 40 00 00 07 DB 20 04 20 04 08 04
					39 00 00 40 00 00 07 DC 20 04 20 04 10 04
					39 00 00 40 00 00 07 DD 20 00 20 00 20 00
					39 00 00 40 00 00 07 DE 20 04 20 04 3F BC
					39 00 00 40 00 00 07 DF 20 04 3F BC 00 00
					39 00 00 40 00 00 07 E0 20 04 3F BC 08 04
					39 00 00 40 00 00 07 E1 20 04 3F BC 10 04
					39 00 00 40 00 00 07 E2 20 04 3F BC 20 04
					39 00 00 40 00 00 07 E3 20 04 3F BC 3F BC
					39 00 00 40 00 00 07 E4 3F BC 00 00 00 00
					39 00 00 40 00 00 07 E5 3F BC 00 00 08 04
					39 00 00 40 00 00 07 E6 3F BC 00 00 10 04
					39 00 00 40 00 00 07 E7 3F BC 00 00 20 04
					39 00 00 40 00 00 07 E8 3F BC 00 00 3F BC
					39 00 00 40 00 00 07 E9 3F BC 08 04 00 00
					39 00 00 40 00 00 07 EA 3F BC 08 04 08 04
					39 00 00 40 00 00 07 EB 3F BC 08 04 10 04
					39 00 00 40 00 00 07 EC 3F BC 08 04 20 04
					39 00 00 40 00 00 07 ED 3F BC 08 04 3F BC
					39 00 00 40 00 00 07 EE 3F BC 10 04 00 00
					39 00 00 40 00 00 07 EF 3F BC 10 04 08 04
					39 00 00 40 00 00 07 F0 3F BC 10 04 10 04
					39 00 00 40 00 00 07 F1 3F BC 10 04 20 04
					39 00 00 40 00 00 07 F2 3F BC 10 04 3F BC
					39 00 00 40 00 00 07 F3 3F BC 20 04 00 00
					39 00 00 40 00 00 07 F4 3F BC 20 04 08 04
					39 00 00 40 00 00 07 F5 3F BC 20 04 10 04
					39 00 00 40 00 00 07 F6 3F BC 20 04 20 04
					39 00 00 40 00 00 07 F7 3F BC 20 04 3F BC
					39 00 00 40 00 00 07 F8 3F BC 3F BC 00 00
					39 00 00 40 00 00 07 F9 3F BC 3F BC 08 04
					39 00 00 40 00 00 07 FA 3F BC 3F BC 10 04
					39 00 00 40 00 00 07 FB 3F BC 3F BC 20 04
					39 00 00 40 00 00 07 FC 3F C0 3F C0 3F C0
					/* 125 point mapping value for DBV2 */
					39 00 00 40 00 00 04 FF 5A A5 71
					39 00 00 40 00 00 07 80 00 00 00 00 00 00
					39 00 00 40 00 00 07 81 00 00 00 00 09 99
					39 00 00 40 00 00 07 82 00 00 00 00 13 33
					39 00 00 40 00 00 07 83 00 00 00 00 20 04
					39 00 00 40 00 00 07 84 00 00 00 00 3F BC
					39 00 00 40 00 00 07 85 00 00 08 04 00 00
					39 00 00 40 00 00 07 86 00 00 08 04 08 04
					39 00 00 40 00 00 07 87 00 00 08 04 10 04
					39 00 00 40 00 00 07 88 00 00 08 04 20 04
					39 00 00 40 00 00 07 89 00 00 08 04 3F BC
					39 00 00 40 00 00 07 8A 00 00 10 04 00 00
					39 00 00 40 00 00 07 8B 00 00 10 04 08 04
					39 00 00 40 00 00 07 8C 00 00 10 04 10 04
					39 00 00 40 00 00 07 8D 00 00 10 04 20 04
					39 00 00 40 00 00 07 8E 00 00 10 04 3F BC
					39 00 00 40 00 00 07 8F 00 00 20 04 00 00
					39 00 00 40 00 00 07 90 00 00 20 04 08 04
					39 00 00 40 00 00 07 91 00 00 20 04 10 04
					39 00 00 40 00 00 07 92 00 00 20 04 20 04
					39 00 00 40 00 00 07 93 00 00 20 04 3F BC
					39 00 00 40 00 00 07 94 00 00 3F BC 00 00
					39 00 00 40 00 00 07 95 00 00 3F BC 08 04
					39 00 00 40 00 00 07 96 00 00 3F BC 10 04
					39 00 00 40 00 00 07 97 00 00 3F BC 20 04
					39 00 00 40 00 00 07 98 00 00 3F BC 3F BC
					39 00 00 40 00 00 07 99 04 CC 00 00 00 00
					39 00 00 40 00 00 07 9A 08 04 00 00 08 04
					39 00 00 40 00 00 07 9B 08 04 00 00 10 04
					39 00 00 40 00 00 07 9C 08 04 00 00 20 04
					39 00 00 40 00 00 07 9D 08 04 00 00 3F BC
					39 00 00 40 00 00 07 9E 08 04 08 04 00 00
					39 00 00 40 00 00 07 9F 04 CC 08 00 09 99
					39 00 00 40 00 00 07 A0 08 04 08 04 10 04
					39 00 00 40 00 00 07 A1 08 04 08 04 20 04
					39 00 00 40 00 00 07 A2 08 04 08 04 3F BC
					39 00 00 40 00 00 07 A3 08 04 10 04 00 00
					39 00 00 40 00 00 07 A4 08 04 10 04 08 04
					39 00 00 40 00 00 07 A5 08 04 10 04 10 04
					39 00 00 40 00 00 07 A6 08 04 10 04 20 04
					39 00 00 40 00 00 07 A7 08 04 10 04 3F BC
					39 00 00 40 00 00 07 A8 08 04 20 04 00 00
					39 00 00 40 00 00 07 A9 08 04 20 04 08 04
					39 00 00 40 00 00 07 AA 08 04 20 04 10 04
					39 00 00 40 00 00 07 AB 08 04 20 04 20 04
					39 00 00 40 00 00 07 AC 08 04 20 04 3F BC
					39 00 00 40 00 00 07 AD 08 04 3F BC 00 00
					39 00 00 40 00 00 07 AE 08 04 3F BC 08 04
					39 00 00 40 00 00 07 AF 08 04 3F BC 10 04
					39 00 00 40 00 00 07 B0 08 04 3F BC 20 04
					39 00 00 40 00 00 07 B1 08 04 3F BC 3F BC
					39 00 00 40 00 00 07 B2 09 99 00 00 00 00
					39 00 00 40 00 00 07 B3 10 04 00 00 08 04
					39 00 00 40 00 00 07 B4 10 04 00 00 10 04
					39 00 00 40 00 00 07 B5 10 04 00 00 20 04
					39 00 00 40 00 00 07 B6 10 04 00 00 3F BC
					39 00 00 40 00 00 07 B7 10 04 08 04 00 00
					39 00 00 40 00 00 07 B8 10 04 08 04 08 04
					39 00 00 40 00 00 07 B9 10 04 08 04 10 04
					39 00 00 40 00 00 07 BA 10 04 08 04 20 04
					39 00 00 40 00 00 07 BB 10 04 08 04 3F BC
					39 00 00 40 00 00 07 BC 10 04 10 04 00 00
					39 00 00 40 00 00 07 BD 10 04 10 04 08 04
					39 00 00 40 00 00 07 BE 09 99 10 04 13 33
					39 00 00 40 00 00 07 BF 10 04 10 04 20 04
					39 00 00 40 00 00 07 C0 10 04 10 04 3F BC
					39 00 00 40 00 00 07 C1 10 04 20 04 00 00
					39 00 00 40 00 00 07 C2 10 04 20 04 08 04
					39 00 00 40 00 00 07 C3 10 04 20 04 10 04
					39 00 00 40 00 00 07 C4 10 04 20 04 20 04
					39 00 00 40 00 00 07 C5 10 04 20 04 3F BC
					39 00 00 40 00 00 07 C6 10 04 3F BC 00 00
					39 00 00 40 00 00 07 C7 10 04 3F BC 08 04
					39 00 00 40 00 00 07 C8 10 04 3F BC 10 04
					39 00 00 40 00 00 07 C9 10 04 3F BC 20 04
					39 00 00 40 00 00 07 CA 10 04 3F BC 3F BC
					39 00 00 40 00 00 07 CB 20 04 00 00 00 00
					39 00 00 40 00 00 07 CC 20 04 00 00 08 04
					39 00 00 40 00 00 07 CD 20 04 00 00 10 04
					39 00 00 40 00 00 07 CE 20 04 00 00 20 04
					39 00 00 40 00 00 07 CF 20 04 00 00 3F BC
					39 00 00 40 00 00 07 D0 20 04 08 04 00 00
					39 00 00 40 00 00 07 D1 20 04 08 04 08 04
					39 00 00 40 00 00 07 D2 20 04 08 04 10 04
					39 00 00 40 00 00 07 D3 20 04 08 04 20 04
					39 00 00 40 00 00 07 D4 20 04 08 04 3F BC
					39 00 00 40 00 00 07 D5 20 04 10 04 00 00
					39 00 00 40 00 00 07 D6 20 04 10 04 08 04
					39 00 00 40 00 00 07 D7 20 04 10 04 10 04
					39 00 00 40 00 00 07 D8 20 04 10 04 20 04
					39 00 00 40 00 00 07 D9 20 04 10 04 3F BC
					39 00 00 40 00 00 07 DA 20 04 20 04 00 00
					39 00 00 40 00 00 07 DB 20 04 20 04 08 04
					39 00 00 40 00 00 07 DC 20 04 20 04 10 04
					39 00 00 40 00 00 07 DD 20 00 20 00 20 00
					39 00 00 40 00 00 07 DE 20 04 20 04 3F BC
					39 00 00 40 00 00 07 DF 20 04 3F BC 00 00
					39 00 00 40 00 00 07 E0 20 04 3F BC 08 04
					39 00 00 40 00 00 07 E1 20 04 3F BC 10 04
					39 00 00 40 00 00 07 E2 20 04 3F BC 20 04
					39 00 00 40 00 00 07 E3 20 04 3F BC 3F BC
					39 00 00 40 00 00 07 E4 3F BC 00 00 00 00
					39 00 00 40 00 00 07 E5 3F BC 00 00 08 04
					39 00 00 40 00 00 07 E6 3F BC 00 00 10 04
					39 00 00 40 00 00 07 E7 3F BC 00 00 20 04
					39 00 00 40 00 00 07 E8 3F BC 00 00 3F BC
					39 00 00 00 00 00 07 E9 3F BC 08 04 00 00
					39 00 00 40 00 00 07 EA 3F BC 08 04 08 04
					39 00 00 40 00 00 07 EB 3F BC 08 04 10 04
					39 00 00 40 00 00 07 EC 3F BC 08 04 20 04
					39 00 00 40 00 00 07 ED 3F BC 08 04 3F BC
					39 00 00 40 00 00 07 EE 3F BC 10 04 00 00
					39 00 00 40 00 00 07 EF 3F BC 10 04 08 04
					39 00 00 40 00 00 07 F0 3F BC 10 04 10 04
					39 00 00 40 00 00 07 F1 3F BC 10 04 20 04
					39 00 00 40 00 00 07 F2 3F BC 10 04 3F BC
					39 00 00 40 00 00 07 F3 3F BC 20 04 00 00
					39 00 00 40 00 00 07 F4 3F BC 20 04 08 04
					39 00 00 40 00 00 07 F5 3F BC 20 04 10 04
					39 00 00 40 00 00 07 F6 3F BC 20 04 20 04
					39 00 00 40 00 00 07 F7 3F BC 20 04 3F BC
					39 00 00 40 00 00 07 F8 3F BC 3F BC 00 00
					39 00 00 40 00 00 07 F9 3F BC 3F BC 08 04
					39 00 00 40 00 00 07 FA 3F BC 3F BC 10 04
					39 00 00 40 00 00 07 FB 3F BC 3F BC 20 04
					39 00 00 00 00 00 07 FC 3F C0 3F C0 3F C0

					05 00 00 00 78 00 01 11 // Sleep OUT
					/* TE raise */
					39 00 00 00 00 00 04 FF 5A A5 22
					39 00 00 00 00 00 08 D8 00 DB 11 10 32 14 14
					39 00 00 00 00 00 08 D9 00 DB 11 10 32 14 14
					39 00 00 00 00 00 08 DA 00 DB 11 10 32 14 14
					39 00 00 00 00 00 08 DB 00 DB 11 10 32 14 14
					39 00 00 00 00 00 0A DC 84 94 BB 00 20 C4 A1 CC 10
					39 00 00 00 00 00 02 DD 01
					39 00 00 00 00 00 02 DE F1
					39 00 00 00 00 00 02 DF 80
					39 00 00 00 00 00 08 E0 02 00 5F 21 00 28 00
					39 00 00 00 00 00 04 FF 5A A5 00
					39 00 00 00 00 00 01 29 // Display ON
				];
				oplus,dsi-aod-off-command = [
					39 00 00 40 00 00 04 FF 5A A5 02
					39 00 00 40 00 00 03 AB AF 82 //TE Shift ON
					39 00 00 40 00 00 03 88 C0 00
					39 00 00 40 00 00 04 FF 5A A5 00
					39 00 00 40 00 00 02 38 00
					39 00 00 00 00 00 05 51 00 00 00 00
				];
				oplus,dsi-ultra-low-power-aod-on-command = [
					39 00 00 40 00 00 04 FF 5A A5 2D
					39 00 00 40 00 00 03 8A 1D 00
					39 00 00 00 00 00 04 FF 5A A5 00
				];
				oplus,dsi-ultra-low-power-aod-off-command = [
					39 00 00 40 00 00 04 FF 5A A5 2D
					39 00 00 40 00 00 03 8A 00 00
					39 00 00 00 00 00 04 FF 5A A5 00
				];
				oplus,dsi-hbm-on-command = [
					39 00 00 00 00 00 03 51 0E E0
				];
				oplus,dsi-hbm-off-command = [
					39 00 00 00 00 00 03 51 0D BB
				];
				oplus,dsi-adfr-min-fps-120hz-command = [
					39 00 00 40 00 00 04 FF 5A A5 2D
					39 00 00 40 00 00 03 83 00 00
					39 00 00 40 00 00 03 84 00 00
					39 00 00 00 00 00 04 FF 5A A5 00
				];
				oplus,dsi-adfr-min-fps-30hz-command = [
					39 00 00 40 00 00 04 FF 5A A5 2D
					39 00 00 40 00 00 03 83 03 00
					39 00 00 40 00 00 03 84 03 00
					39 00 00 00 00 00 04 FF 5A A5 00
				];
				oplus,dsi-multi-te-enable-command = [
					39 00 00 40 00 00 04 FF 5A A5 2D
					39 00 00 40 00 00 03 83 03 00
					39 00 00 40 00 00 03 84 03 00
					39 00 00 40 00 00 04 FF 5A A5 20
					39 00 00 40 00 00 02 BB 96
					39 00 00 00 00 00 04 FF 5A A5 00
				];
				oplus,dsi-multi-te-disable-command = [
					39 00 00 40 00 00 04 FF 5A A5 2D
					39 00 00 40 00 00 03 83 00 00
					39 00 00 40 00 00 03 84 00 00
					39 00 00 40 00 00 04 FF 5A A5 20
					39 00 00 40 00 00 02 BB 06
					39 00 00 00 00 00 04 FF 5A A5 00
				];
				oplus,dsi-pwm-switch-1to3pul-command = [
					39 00 00 40 00 00 04 FF 5A A5 53
					39 00 00 40 00 00 03 85 CC E1 // Normal Demura
					39 00 00 40 00 00 04 FF 5A A5 00
					39 00 00 00 00 00 02 60 00
				];
				oplus,dsi-pwm-switch-3to1pul-command = [
					39 00 00 40 00 00 04 FF 5A A5 53
					39 00 00 40 00 00 03 85 CC E3 // DC Demura
					39 00 00 40 00 00 04 FF 5A A5 00
					39 00 00 00 00 00 02 60 01
				];

				oplus,dsi-timing-switch-command-state = "dsi_hs_mode";
				oplus,dsi-timing-switch-1pulse-command-state = "dsi_hs_mode";
				oplus,dsi-on-command-state = "dsi_lp_mode";
				oplus,dsi-aod-off-command-state = "dsi_ls_mode";
				oplus,dsi-ultra-low-power-aod-off-command-state = "dsi_ls_mode";
				oplus,dsi-ultra-low-power-aod-on-command-state = "dsi_ls_mode";
				oplus,dsi-hbm-on-command-state = "dsi_hs_mode";
				oplus,dsi-hbm-off-command-state = "dsi_hs_mode";
				oplus,dsi-auto-off-minfps-command-state = "dsi_hs_mode";
				oplus,dsi-pwm-switch-1to3pul-command-state = "dsi_hs_mode";
				oplus,dsi-pwm-switch-3to1pul-command-state = "dsi_hs_mode";
				oplus,dsi-adfr-min-fps-120hz-command-state = "dsi_hs_mode";
				oplus,dsi-adfr-min-fps-30hz-command-state = "dsi_hs_mode";
				oplus,dsi-multi-te-disable-command-state = "dsi_hs_mode";
				oplus,dsi-multi-te-enable-command-state = "dsi_hs_mode";
				oplus,dsc-params-entries = <&dsc_params>;
				oplus,spr-params-entries = <&spr_params>;
				oplus,phy-timcon {
					hs-trail = <14>;
					clk-trail = <15>;
				};
				oplus,dyn-fps {
					switch_en = <1>;
					vact_timing_fps = <120>;
					apollo_limit_superior_us = <4900>;
					apollo_limit_inferior_us = <6750>;
					apollo_transfer_time_us = <6200>;
				};
				oplus,display-mode {
					oplus,display-mode@0 {
						hdisplay = <1264>;
						vdisplay = <2780>;
						fhd-hfp = <9>;
						fhd-hsa = <2>;
						fhd-hbp = <21>;
						fhd-vfp = <52>;
						fhd-vsa = <14>;
						fhd-vbp = <22>;
						hskew = <2>;
					};
					oplus,display-mode@1 {
						hdisplay = <1080>;
						vdisplay = <2376>;
						fhd-hfp = <9>;
						fhd-hsa = <2>;
						fhd-hbp = <21>;
						fhd-vfp = <66>;
						fhd-vsa = <24>;
						fhd-vbp = <36>;
						hskew = <2>;
					};
				};
			};
		};
	};
};

&panel_ac180_p_3_a0020_dsi_cmd {
	oplus,dsi-display-panel@1 {
		res-switch = <2>;
		/* Hardware config */
		oplus,panel-supply-entries = <&dsi_panel_pwr_supply>;
		oplus,panel-power-on-sequence = "1", "vddio", "5", "vddr", "5", "vci", "1";
		oplus,panel-power-off-sequence = "2", "vci", "5", "vddr", "5", "vddio", "1";
		reset-gpios = <&pio 90 0>;
		oplus,panel-reset-sequence = <2 10>, <1 1>, <0 1>, <1 20>;
		/* Panel config */
		oplus,dsi-serial-number-enabled=<1>;
		oplus,dsi-serial-number-switch-page;
		oplus,dsi-serial-number-index= <0>;
		oplus,dsi-serial-number-switch-page-command= <0xFF 0x5A 0xA5 0x1D>;
		oplus,dsi-serial-number-default-switch-page-command= <0xFF 0x5A 0xA5 0x00>;
		oplus,dsi-serial-number-reg= <0x82>;
		oplus,dsi-serial-number-read-count= <7>;
		oplus,dsi-serial-number-year-offset= <0>;
		/* PWM config */
		oplus,pwm-turbo-support = <1>; /* 0 not support, 1 with switch, 2 Global high frequency pwm without switch */
		oplus,pwm-switch-backlight-threshold = <0>;
		oplus,pwm-onepulse-support = <1>;
		oplus,pwm-onepulse-enabled = <0>;
		oplus,pwm-turbo-wait-te = <1>;
		/* ADFR config */
		oplus-adfr-config = <0x201>;
		oplus-adfr-test-te-gpios = <&pio 103 0>;
		/* OFP config */
		oplus,ofp-fp-type = <0x10>;
		oplus,ofp-longrui-aod-config = <0x02>;
		/* ext_params */
		oplus,panel-type = <0>;
		oplus,lane-swap-en = <0>;
		oplus,lane-swap = <
			MIPITX_PHY_LANE_0 MIPITX_PHY_LANE_1 MIPITX_PHY_LANE_3 MIPITX_PHY_LANE_2 MIPITX_PHY_LANE_CK MIPITX_PHY_LANE_RX
			MIPITX_PHY_LANE_0 MIPITX_PHY_LANE_1 MIPITX_PHY_LANE_3 MIPITX_PHY_LANE_2 MIPITX_PHY_LANE_CK MIPITX_PHY_LANE_RX
		>;
		oplus,lcm-color-mode = <MTK_DRM_COLOR_MODE_DISPLAY_P3>;
		oplus,output-mode = <MTK_PANEL_DSC_SINGLE_PORT>;
		oplus,panel-bpp = <10>;
		oplus,physical-width-um = <71289>;
		oplus,physical-height-um = <156792>;
		/* color */
		oplus,color-vivid-status;
		oplus,color-srgb-status;
		// oplus,color-softiris-status;
		// oplus,color-dual-panel-status;
		oplus,color-dual-brightness-status;
		oplus,color-oplus-calibrate-status;
		// oplus,color-samsung-status;
		oplus,color-loading-status;
		oplus,color-2nit-status;
		// oplus,color-nature-profession-status;
		/* ESD */
		oplus,cust-esd-check = <1>;
		oplus,esd-check-enable = <1>;
		oplus,esd_check_cmd = [
			0A
		];
		oplus,esd_check_count = [
			01
		];
		oplus,esd_check_value = [
			9C
		];
		oplus,esd_check_mask = [
			FF
		];
	};
};
